[part 4 of 6: packages /DBC_SysDesc_P_CANFD/Pkg_Cluster to /DBC_SysDesc_P_CANFD/Pkg_CompuMethod]
AUTOSAR XML (schema 4-2-2)
package /DBC_SysDesc_P_CANFD/Pkg_Cluster  (continued)
  can cluster P_CANFD: baudrate=500000, protocol-name=CAN, can-fd-baudrate=2000000  (continued)
    can physical channel P_CANFD_Channel: comm-connectors=Conn_P_CANFD_MVCU  (continued)
      frame MCUM_0xCA: id 0xCA, from MVCU, frame-length=32, can-addressing-mode=STANDARD, can-fd-frame-support=true, can-frame-tx-behavior=CAN-FD
        carries pdu MCUM_0xCA: packing-byte-order=little-endian, start-position=0, update-indication-bit-position=-1
        pdu MCUM_0xCA: length=32, transmission-mode-false-timing=cyclic-timing={time-offset=0.0, time-period=0.01}, transmission-mode-true-timing=cyclic-timing={time-offset=0.0, time-period=0.01}
          transmission-mode-conditions:
            {data-filter={data-filter-type=ALWAYS, max=255, min=0, offset=0}, i-signal-in-i-pdu=MCUM_CRC_CA}
            {data-filter={data-filter-type=ALWAYS, max=15, min=0, offset=0}, i-signal-in-i-pdu=MCUM_RollingCounter_CA}
            {data-filter={data-filter-type=ALWAYS, max=3, min=0, offset=0}, i-signal-in-i-pdu=MCUM_WarningLevel}
            {data-filter={data-filter-type=ALWAYS, max=3, min=0, offset=0}, i-signal-in-i-pdu=MCUM_SelfCheckSts}
            {data-filter={data-filter-type=ALWAYS, max=3, min=0, offset=0}, i-signal-in-i-pdu=MCUM_DrvMotorWorkSts}
            {data-filter={data-filter-type=ALWAYS, max=1, min=0, offset=0}, i-signal-in-i-pdu=MCUM_PowerReduceSts}
            {data-filter={data-filter-type=ALWAYS, max=1, min=0, offset=0}, i-signal-in-i-pdu=MCUM_SystemError}
            {data-filter={data-filter-type=NEW-IS-WITHIN, max=47000, min=0}, i-signal-in-i-pdu=MCUM_DrvMotorRPM}
            {data-filter={data-filter-type=NEW-IS-WITHIN, max=10000, min=0}, i-signal-in-i-pdu=MCUM_ActualTorqueFB}
            {data-filter={data-filter-type=ALWAYS, max=1, min=0, offset=0}, i-signal-in-i-pdu=MCUM_HWRdcFault}
            {data-filter={data-filter-type=ALWAYS, max=1, min=0, offset=0}, i-signal-in-i-pdu=MCUM_LVSystemError}
            {data-filter={data-filter-type=ALWAYS, max=1, min=0, offset=0}, i-signal-in-i-pdu=MCUM_HighVoltPowerOffReq}
            {data-filter={data-filter-type=ALWAYS, max=1, min=0, offset=0}, i-signal-in-i-pdu=MCUM_HVILSts}
            {data-filter={data-filter-type=ALWAYS, max=3, min=0, offset=0}, i-signal-in-i-pdu=MCUM_DragSts}
            {data-filter={data-filter-type=ALWAYS, max=1, min=0, offset=0}, i-signal-in-i-pdu=MCUM_CtrlMode}
            {data-filter={data-filter-type=ALWAYS, max=1, min=0, offset=0}, i-signal-in-i-pdu=MCUM_MotorTempAlarm}
            {data-filter={data-filter-type=ALWAYS, max=1, min=0, offset=0}, i-signal-in-i-pdu=MCUM_HVSystemError}
            {data-filter={data-filter-type=ALWAYS, max=1, min=0, offset=0}, i-signal-in-i-pdu=MCUM_MILlampReq}
            {data-filter={data-filter-type=ALWAYS, max=3, min=0, offset=0}, i-signal-in-i-pdu=MCUM_SeriousWarning_Level}
            {data-filter={data-filter-type=ALWAYS, max=1, min=0, offset=0}, i-signal-in-i-pdu=MCUM_DrvMotorRPMVD}
            {data-filter={data-filter-type=ALWAYS, max=1, min=0, offset=0}, i-signal-in-i-pdu=MCUM_ActualTorqueFBVD}
            {data-filter={data-filter-type=ALWAYS, max=1, min=0, offset=0}, i-signal-in-i-pdu=MCUM_CtrlModeVD}
            {data-filter={data-filter-type=NEW-IS-WITHIN, max=10000, min=0}, i-signal-in-i-pdu=MCUM_MaxTorqueAllow}
            {data-filter={data-filter-type=NEW-IS-WITHIN, max=34000, min=0}, i-signal-in-i-pdu=MCUM_MaxSpeedAllow}
            {data-filter={data-filter-type=ALWAYS, max=10, min=0, offset=0}, i-signal-in-i-pdu=MCUM_WaterPumpLevlReq}
            {data-filter={data-filter-type=ALWAYS, max=3, min=0, offset=0}, i-signal-in-i-pdu=MCUM_ActiveReleaseSts}
            {data-filter={data-filter-type=ALWAYS, max=1, min=0, offset=0}, i-signal-in-i-pdu=MCUM_DCChargRelaySts}
            {data-filter={data-filter-type=ALWAYS, max=1, min=0, offset=0}, i-signal-in-i-pdu=MCUM_Fault_DCChargRelay}
            {data-filter={data-filter-type=NEW-IS-WITHIN, max=10000, min=0}, i-signal-in-i-pdu=MCUM_MinTorqueAllow}
            {data-filter={data-filter-type=NEW-IS-WITHIN, max=10000, min=0, offset=0}, i-signal-in-i-pdu=MCUM_MainWireVolt}
            {data-filter={data-filter-type=ALWAYS, max=250, min=0}, i-signal-in-i-pdu=MCUM_MotorTemp}
            {data-filter={data-filter-type=ALWAYS, max=250, min=0}, i-signal-in-i-pdu=MCUM_IGBTTemp}
            {data-filter={data-filter-type=ALWAYS, max=250, min=0}, i-signal-in-i-pdu=MCUM_InletTemp}
            {data-filter={data-filter-type=NEW-IS-WITHIN, max=20000, min=0}, i-signal-in-i-pdu=MCUM_MainWireCurr}
            {data-filter={data-filter-type=ALWAYS, max=1, min=0, offset=0}, i-signal-in-i-pdu=MCUM_TMS_MotSelfHeatEnSts}
            {data-filter={data-filter-type=ALWAYS, max=7, min=0, offset=0}, i-signal-in-i-pdu=MCUM_TMS_MotSelfHeatLvlFb}
            {data-filter={data-filter-type=ALWAYS, max=1, min=0, offset=0}, i-signal-in-i-pdu=MCUM_HeatPwrAllwd}
            {data-filter={data-filter-type=ALWAYS, max=3, min=0, offset=0}, i-signal-in-i-pdu=MCUM_HeatFdBck}
            {data-filter={data-filter-type=ALWAYS, max=1, min=0, offset=0}, i-signal-in-i-pdu=MCUM_RPowerReduceSts}
            {data-filter={data-filter-type=ALWAYS, max=128, min=0, offset=0}, i-signal-in-i-pdu=MCUM_HeatPwrAct}
            {data-filter={data-filter-type=ALWAYS, max=128, min=0, offset=0}, i-signal-in-i-pdu=MCUM_HeatPwrMax}
            {data-filter={data-filter-type=ALWAYS, max=31, min=0, offset=0}, i-signal-in-i-pdu=MCUM_HeatPwrAval}
            {data-filter={data-filter-type=ALWAYS, max=1, min=0, offset=0}, i-signal-in-i-pdu=MCUM_RCtrlMode}
            {data-filter={data-filter-type=ALWAYS, max=3, min=0, offset=0}, i-signal-in-i-pdu=MCUM_RWarningLevel}
            {data-filter={data-filter-type=ALWAYS, max=3, min=0, offset=0}, i-signal-in-i-pdu=MCUM_RSelfCheckSts}
            {data-filter={data-filter-type=ALWAYS, max=3, min=0, offset=0}, i-signal-in-i-pdu=MCUM_RDrvMotorWorkSts}
            {data-filter={data-filter-type=ALWAYS, max=1, min=0, offset=0}, i-signal-in-i-pdu=MCUM_RCtrlModeVD}
            {data-filter={data-filter-type=ALWAYS, max=1, min=0, offset=0}, i-signal-in-i-pdu=MCUM_RHWRdcFault}
            {data-filter={data-filter-type=ALWAYS, max=1, min=0, offset=0}, i-signal-in-i-pdu=MCUM_RDrvMotorRPMVD}
            {data-filter={data-filter-type=ALWAYS, max=1, min=0, offset=0}, i-signal-in-i-pdu=MCUM_RActualTorqueFBVD}
            {data-filter={data-filter-type=ALWAYS, max=65535, min=0, offset=0}, i-signal-in-i-pdu=MCUM_RDrvMotorRPM}
            {data-filter={data-filter-type=ALWAYS, max=65535, min=0, offset=0}, i-signal-in-i-pdu=MCUM_RActualTorqueFB}
          signal MCUM_CRC_CA: start 0, 8 bit, little-endian, init-value=0, base-type=uint8, implementation-data-type=DT_MCUM_CRC_CA, update-indication-bit-position=-1
          signal MCUM_RollingCounter_CA: start 8, 4 bit, little-endian, init-value=0, base-type=uint8, implementation-data-type=DT_MCUM_RollingCounter_CA, update-indication-bit-position=-1
          signal MCUM_WarningLevel: start 16, 2 bit, little-endian, init-value=0, base-type=uint8, implementation-data-type=DT_MCUM_WarningLevel, update-indication-bit-position=-1
          signal MCUM_SelfCheckSts: start 18, 2 bit, little-endian, init-value=0, base-type=uint8, implementation-data-type=DT_MCUM_SelfCheckSts, update-indication-bit-position=-1
          signal MCUM_DrvMotorWorkSts: start 20, 2 bit, little-endian, init-value=0, base-type=uint8, implementation-data-type=DT_MCUM_DrvMotorWorkSts, update-indication-bit-position=-1
          signal MCUM_PowerReduceSts: start 22, 1 bit, little-endian, init-value=0, base-type=uint8, implementation-data-type=DT_MCUM_PowerReduceSts, update-indication-bit-position=-1
          signal MCUM_SystemError: start 23, 1 bit, little-endian, init-value=0, base-type=uint8, implementation-data-type=DT_MCUM_SystemError, update-indication-bit-position=-1
          signal MCUM_DrvMotorRPM: start 24, 16 bit, little-endian, init-value=0, base-type=uint16, implementation-data-type=DT_MCUM_DrvMotorRPM, update-indication-bit-position=-1
          signal MCUM_ActualTorqueFB: start 40, 16 bit, little-endian, init-value=0, base-type=uint16, implementation-data-type=DT_MCUM_ActualTorqueFB, update-indication-bit-position=-1
          signal MCUM_HWRdcFault: start 56, 1 bit, little-endian, init-value=0, base-type=uint8, implementation-data-type=DT_MCUM_HWRdcFault, update-indication-bit-position=-1
          signal MCUM_LVSystemError: start 57, 1 bit, little-endian, init-value=0, base-type=uint8, implementation-data-type=DT_MCUM_LVSystemError, update-indication-bit-position=-1
          signal MCUM_HighVoltPowerOffReq: start 58, 1 bit, little-endian, init-value=0, base-type=uint8, implementation-data-type=DT_MCUM_HighVoltPowerOffReq, update-indication-bit-position=-1
          signal MCUM_HVILSts: start 59, 1 bit, little-endian, init-value=0, base-type=uint8, implementation-data-type=DT_MCUM_HVILSts, update-indication-bit-position=-1
          signal MCUM_DragSts: start 60, 2 bit, little-endian, init-value=0, base-type=uint8, implementation-data-type=DT_MCUM_DragSts, update-indication-bit-position=-1
          signal MCUM_CtrlMode: start 62, 1 bit, little-endian, init-value=0, base-type=uint8, implementation-data-type=DT_MCUM_CtrlMode, update-indication-bit-position=-1
          signal MCUM_MotorTempAlarm: start 63, 1 bit, little-endian, init-value=0, base-type=uint8, implementation-data-type=DT_MCUM_MotorTempAlarm, update-indication-bit-position=-1
          signal MCUM_HVSystemError: start 64, 1 bit, little-endian, init-value=0, base-type=uint8, implementation-data-type=DT_MCUM_HVSystemError, update-indication-bit-position=-1
          signal MCUM_MILlampReq: start 65, 1 bit, little-endian, init-value=0, base-type=uint8, implementation-data-type=DT_MCUM_MILlampReq, update-indication-bit-position=-1
          signal MCUM_SeriousWarning_Level: start 66, 2 bit, little-endian, init-value=0, base-type=uint8, implementation-data-type=DT_MCUM_SeriousWarning_Level, update-indication-bit-position=-1
          signal MCUM_DrvMotorRPMVD: start 68, 1 bit, little-endian, init-value=0, base-type=uint8, implementation-data-type=DT_MCUM_DrvMotorRPMVD, update-indication-bit-position=-1
          signal MCUM_ActualTorqueFBVD: start 69, 1 bit, little-endian, init-value=0, base-type=uint8, implementation-data-type=DT_MCUM_ActualTorqueFBVD, update-indication-bit-position=-1
          signal MCUM_CtrlModeVD: start 70, 1 bit, little-endian, init-value=0, base-type=uint8, implementation-data-type=DT_MCUM_CtrlModeVD, update-indication-bit-position=-1
          signal MCUM_MaxTorqueAllow: start 72, 16 bit, little-endian, init-value=0, base-type=uint16, implementation-data-type=DT_MCUM_MaxTorqueAllow, update-indication-bit-position=-1
          signal MCUM_MaxSpeedAllow: start 88, 16 bit, little-endian, init-value=0, base-type=uint16, implementation-data-type=DT_MCUM_MaxSpeedAllow, update-indication-bit-position=-1
          signal MCUM_WaterPumpLevlReq: start 104, 4 bit, little-endian, init-value=0, base-type=uint8, implementation-data-type=DT_MCUM_WaterPumpLevlReq, update-indication-bit-position=-1
          signal MCUM_ActiveReleaseSts: start 108, 2 bit, little-endian, init-value=0, base-type=uint8, implementation-data-type=DT_MCUM_ActiveReleaseSts, update-indication-bit-position=-1
          signal MCUM_DCChargRelaySts: start 110, 1 bit, little-endian, init-value=0, base-type=uint8, implementation-data-type=DT_MCUM_DCChargRelaySts, update-indication-bit-position=-1
          signal MCUM_Fault_DCChargRelay: start 111, 1 bit, little-endian, init-value=0, base-type=uint8, implementation-data-type=DT_MCUM_Fault_DCChargRelay, update-indication-bit-position=-1
          signal MCUM_MinTorqueAllow: start 112, 16 bit, little-endian, init-value=0, base-type=uint16, implementation-data-type=DT_MCUM_MinTorqueAllow, update-indication-bit-position=-1
          signal MCUM_MainWireVolt: start 128, 16 bit, little-endian, init-value=0, base-type=uint16, implementation-data-type=DT_MCUM_MainWireVolt, update-indication-bit-position=-1
          signal MCUM_MotorTemp: start 144, 8 bit, little-endian, init-value=0, base-type=uint8, implementation-data-type=DT_MCUM_MotorTemp, update-indication-bit-position=-1
          signal MCUM_IGBTTemp: start 152, 8 bit, little-endian, init-value=0, base-type=uint8, implementation-data-type=DT_MCUM_IGBTTemp, update-indication-bit-position=-1
          signal MCUM_InletTemp: start 160, 8 bit, little-endian, init-value=0, base-type=uint8, implementation-data-type=DT_MCUM_InletTemp, update-indication-bit-position=-1
          signal MCUM_MainWireCurr: start 168, 16 bit, little-endian, init-value=0, base-type=uint16, implementation-data-type=DT_MCUM_MainWireCurr, update-indication-bit-position=-1
          signal MCUM_TMS_MotSelfHeatEnSts: start 184, 1 bit, little-endian, init-value=0, base-type=uint8, implementation-data-type=DT_MCUM_TMS_MotSelfHeatEnSts, update-indication-bit-position=-1
          signal MCUM_TMS_MotSelfHeatLvlFb: start 185, 3 bit, little-endian, init-value=0, base-type=uint8, implementation-data-type=DT_MCUM_TMS_MotSelfHeatLvlFb, update-indication-bit-position=-1
          signal MCUM_HeatPwrAllwd: start 188, 1 bit, little-endian, init-value=0, base-type=uint8, implementation-data-type=DT_MCUM_HeatPwrAllwd, update-indication-bit-position=-1
          signal MCUM_HeatFdBck: start 189, 2 bit, little-endian, init-value=0, base-type=uint8, implementation-data-type=DT_MCUM_HeatFdBck, update-indication-bit-position=-1
          signal MCUM_RPowerReduceSts: start 191, 1 bit, little-endian, init-value=0, base-type=uint8, implementation-data-type=DT_MCUM_RPowerReduceSts, update-indication-bit-position=-1
          signal MCUM_HeatPwrAct: start 192, 8 bit, little-endian, init-value=0, base-type=uint8, implementation-data-type=DT_MCUM_HeatPwrAct, update-indication-bit-position=-1
          signal MCUM_HeatPwrMax: start 200, 8 bit, little-endian, init-value=0, base-type=uint8, implementation-data-type=DT_MCUM_HeatPwrMax, update-indication-bit-position=-1
          signal MCUM_HeatPwrAval: start 208, 5 bit, little-endian, init-value=0, base-type=uint8, implementation-data-type=DT_MCUM_HeatPwrAval, update-indication-bit-position=-1
          signal MCUM_RCtrlMode: start 213, 1 bit, little-endian, init-value=0, base-type=uint8, implementation-data-type=DT_MCUM_RCtrlMode, update-indication-bit-position=-1
          signal MCUM_RWarningLevel: start 214, 2 bit, little-endian, init-value=0, base-type=uint8, implementation-data-type=DT_MCUM_RWarningLevel, update-indication-bit-position=-1
          signal MCUM_RSelfCheckSts: start 216, 2 bit, little-endian, init-value=0, base-type=uint8, implementation-data-type=DT_MCUM_RSelfCheckSts, update-indication-bit-position=-1
          signal MCUM_RDrvMotorWorkSts: start 218, 2 bit, little-endian, init-value=0, base-type=uint8, implementation-data-type=DT_MCUM_RDrvMotorWorkSts, update-indication-bit-position=-1
          signal MCUM_RCtrlModeVD: start 220, 1 bit, little-endian, init-value=0, base-type=uint8, implementation-data-type=DT_MCUM_RCtrlModeVD, update-indication-bit-position=-1
          signal MCUM_RHWRdcFault: start 221, 1 bit, little-endian, init-value=0, base-type=uint8, implementation-data-type=DT_MCUM_RHWRdcFault, update-indication-bit-position=-1
          signal MCUM_RDrvMotorRPMVD: start 222, 1 bit, little-endian, init-value=0, base-type=uint8, implementation-data-type=DT_MCUM_RDrvMotorRPMVD, update-indication-bit-position=-1
          signal MCUM_RActualTorqueFBVD: start 223, 1 bit, little-endian, init-value=0, base-type=uint8, implementation-data-type=DT_MCUM_RActualTorqueFBVD, update-indication-bit-position=-1
          signal MCUM_RDrvMotorRPM: start 224, 16 bit, little-endian, init-value=0, base-type=uint16, implementation-data-type=DT_MCUM_RDrvMotorRPM, update-indication-bit-position=-1
          signal MCUM_RActualTorqueFB: start 240, 16 bit, little-endian, init-value=0, base-type=uint16, implementation-data-type=DT_MCUM_RActualTorqueFB, update-indication-bit-position=-1
      frame MCUM_0x6F8: id 0x6F8, from MVCU, frame-length=64, can-addressing-mode=STANDARD, can-fd-frame-support=true, can-frame-tx-behavior=CAN-FD
        carries pdu MCUM_0x6F8: packing-byte-order=little-endian, start-position=0, update-indication-bit-position=-1
        pdu MCUM_0x6F8: length=64, transmission-mode-false-timing=cyclic-timing={time-offset=0.0, time-period=1.0}, transmission-mode-true-timing=cyclic-timing={time-offset=0.0, time-period=1.0}
          transmission-mode-conditions:
            {data-filter={data-filter-type=ALWAYS, max=255, min=0, offset=0}, i-signal-in-i-pdu=MCUM_UDS_SW{1..10}}
            {data-filter={data-filter-type=ALWAYS, max=255, min=0, offset=0}, i-signal-in-i-pdu=MCUM_UDS_HW{1..10}}
            {data-filter={data-filter-type=ALWAYS, max=255, min=0, offset=0}, i-signal-in-i-pdu=MCUM_UDS_Boot{1..10}}
            {data-filter={data-filter-type=ALWAYS, max=255, min=0, offset=0}, i-signal-in-i-pdu=MCUM_UDS_ProductModel{1..16}}
            {data-filter={data-filter-type=ALWAYS, max=255, min=0, offset=0}, i-signal-in-i-pdu=MCUM_UDS_Supplier{1..6}}
          signal MCUM_UDS_SW1: start 0, 8 bit, little-endian, init-value=0, base-type=uint8, implementation-data-type=DT_MCUM_UDS_SW1, update-indication-bit-position=-1
          signal MCUM_UDS_SW2: start 8, 8 bit, little-endian, init-value=0, base-type=uint8, implementation-data-type=DT_MCUM_UDS_SW2, update-indication-bit-position=-1
          signal MCUM_UDS_SW3: start 16, 8 bit, little-endian, init-value=0, base-type=uint8, implementation-data-type=DT_MCUM_UDS_SW3, update-indication-bit-position=-1
          signal MCUM_UDS_SW4: start 24, 8 bit, little-endian, init-value=0, base-type=uint8, implementation-data-type=DT_MCUM_UDS_SW4, update-indication-bit-position=-1
          signal MCUM_UDS_SW5: start 32, 8 bit, little-endian, init-value=0, base-type=uint8, implementation-data-type=DT_MCUM_UDS_SW5, update-indication-bit-position=-1
          signal MCUM_UDS_SW6: start 40, 8 bit, little-endian, init-value=0, base-type=uint8, implementation-data-type=DT_MCUM_UDS_SW6, update-indication-bit-position=-1
          signal MCUM_UDS_SW7: start 48, 8 bit, little-endian, init-value=0, base-type=uint8, implementation-data-type=DT_MCUM_UDS_SW7, update-indication-bit-position=-1
          signal MCUM_UDS_SW8: start 56, 8 bit, little-endian, init-value=0, base-type=uint8, implementation-data-type=DT_MCUM_UDS_SW8, update-indication-bit-position=-1
          signal MCUM_UDS_SW9: start 64, 8 bit, little-endian, init-value=0, base-type=uint8, implementation-data-type=DT_MCUM_UDS_SW9, update-indication-bit-position=-1
          signal MCUM_UDS_SW10: start 72, 8 bit, little-endian, init-value=0, base-type=uint8, implementation-data-type=DT_MCUM_UDS_SW10, update-indication-bit-position=-1
          signal MCUM_UDS_HW1: start 80, 8 bit, little-endian, init-value=0, base-type=uint8, implementation-data-type=DT_MCUM_UDS_HW1, update-indication-bit-position=-1
          signal MCUM_UDS_HW2: start 88, 8 bit, little-endian, init-value=0, base-type=uint8, implementation-data-type=DT_MCUM_UDS_HW2, update-indication-bit-position=-1
          signal MCUM_UDS_HW3: start 96, 8 bit, little-endian, init-value=0, base-type=uint8, implementation-data-type=DT_MCUM_UDS_HW3, update-indication-bit-position=-1
          signal MCUM_UDS_HW4: start 104, 8 bit, little-endian, init-value=0, base-type=uint8, implementation-data-type=DT_MCUM_UDS_HW4, update-indication-bit-position=-1
          signal MCUM_UDS_HW5: start 112, 8 bit, little-endian, init-value=0, base-type=uint8, implementation-data-type=DT_MCUM_UDS_HW5, update-indication-bit-position=-1
          signal MCUM_UDS_HW6: start 120, 8 bit, little-endian, init-value=0, base-type=uint8, implementation-data-type=DT_MCUM_UDS_HW6, update-indication-bit-position=-1
          signal MCUM_UDS_HW7: start 128, 8 bit, little-endian, init-value=0, base-type=uint8, implementation-data-type=DT_MCUM_UDS_HW7, update-indication-bit-position=-1
          signal MCUM_UDS_HW8: start 136, 8 bit, little-endian, init-value=0, base-type=uint8, implementation-data-type=DT_MCUM_UDS_HW8, update-indication-bit-position=-1
          signal MCUM_UDS_HW9: start 144, 8 bit, little-endian, init-value=0, base-type=uint8, implementation-data-type=DT_MCUM_UDS_HW9, update-indication-bit-position=-1
          signal MCUM_UDS_HW10: start 152, 8 bit, little-endian, init-value=0, base-type=uint8, implementation-data-type=DT_MCUM_UDS_HW10, update-indication-bit-position=-1
          signal MCUM_UDS_Boot1: start 160, 8 bit, little-endian, init-value=0, base-type=uint8, implementation-data-type=DT_MCUM_UDS_Boot1, update-indication-bit-position=-1
          signal MCUM_UDS_Boot2: start 168, 8 bit, little-endian, init-value=0, base-type=uint8, implementation-data-type=DT_MCUM_UDS_Boot2, update-indication-bit-position=-1
          signal MCUM_UDS_Boot3: start 176, 8 bit, little-endian, init-value=0, base-type=uint8, implementation-data-type=DT_MCUM_UDS_Boot3, update-indication-bit-position=-1
          signal MCUM_UDS_Boot4: start 184, 8 bit, little-endian, init-value=0, base-type=uint8, implementation-data-type=DT_MCUM_UDS_Boot4, update-indication-bit-position=-1
          signal MCUM_UDS_Boot5: start 192, 8 bit, little-endian, init-value=0, base-type=uint8, implementation-data-type=DT_MCUM_UDS_Boot5, update-indication-bit-position=-1
          signal MCUM_UDS_Boot6: start 200, 8 bit, little-endian, init-value=0, base-type=uint8, implementation-data-type=DT_MCUM_UDS_Boot6, update-indication-bit-position=-1
          signal MCUM_UDS_Boot7: start 208, 8 bit, little-endian, init-value=0, base-type=uint8, implementation-data-type=DT_MCUM_UDS_Boot7, update-indication-bit-position=-1
          signal MCUM_UDS_Boot8: start 216, 8 bit, little-endian, init-value=0, base-type=uint8, implementation-data-type=DT_MCUM_UDS_Boot8, update-indication-bit-position=-1
          signal MCUM_UDS_Boot9: start 224, 8 bit, little-endian, init-value=0, base-type=uint8, implementation-data-type=DT_MCUM_UDS_Boot9, update-indication-bit-position=-1
          signal MCUM_UDS_Boot10: start 232, 8 bit, little-endian, init-value=0, base-type=uint8, implementation-data-type=DT_MCUM_UDS_Boot10, update-indication-bit-position=-1
          signal MCUM_UDS_ProductModel1: start 240, 8 bit, little-endian, init-value=0, base-type=uint8, implementation-data-type=DT_MCUM_UDS_ProductModel1, update-indication-bit-position=-1
          signal MCUM_UDS_ProductModel2: start 248, 8 bit, little-endian, init-value=0, base-type=uint8, implementation-data-type=DT_MCUM_UDS_ProductModel2, update-indication-bit-position=-1
          signal MCUM_UDS_ProductModel3: start 256, 8 bit, little-endian, init-value=0, base-type=uint8, implementation-data-type=DT_MCUM_UDS_ProductModel3, update-indication-bit-position=-1
          signal MCUM_UDS_ProductModel4: start 264, 8 bit, little-endian, init-value=0, base-type=uint8, implementation-data-type=DT_MCUM_UDS_ProductModel4, update-indication-bit-position=-1
          signal MCUM_UDS_ProductModel5: start 272, 8 bit, little-endian, init-value=0, base-type=uint8, implementation-data-type=DT_MCUM_UDS_ProductModel5, update-indication-bit-position=-1
          signal MCUM_UDS_ProductModel6: start 280, 8 bit, little-endian, init-value=0, base-type=uint8, implementation-data-type=DT_MCUM_UDS_ProductModel6, update-indication-bit-position=-1
          signal MCUM_UDS_ProductModel7: start 288, 8 bit, little-endian, init-value=0, base-type=uint8, implementation-data-type=DT_MCUM_UDS_ProductModel7, update-indication-bit-position=-1
          signal MCUM_UDS_ProductModel8: start 296, 8 bit, little-endian, init-value=0, base-type=uint8, implementation-data-type=DT_MCUM_UDS_ProductModel8, update-indication-bit-position=-1
          signal MCUM_UDS_ProductModel9: start 304, 8 bit, little-endian, init-value=0, base-type=uint8, implementation-data-type=DT_MCUM_UDS_ProductModel9, update-indication-bit-position=-1
          signal MCUM_UDS_ProductModel10: start 312, 8 bit, little-endian, init-value=0, base-type=uint8, implementation-data-type=DT_MCUM_UDS_ProductModel10, update-indication-bit-position=-1
          signal MCUM_UDS_ProductModel11: start 320, 8 bit, little-endian, init-value=0, base-type=uint8, implementation-data-type=DT_MCUM_UDS_ProductModel11, update-indication-bit-position=-1
          signal MCUM_UDS_ProductModel12: start 328, 8 bit, little-endian, init-value=0, base-type=uint8, implementation-data-type=DT_MCUM_UDS_ProductModel12, update-indication-bit-position=-1
          signal MCUM_UDS_ProductModel13: start 336, 8 bit, little-endian, init-value=0, base-type=uint8, implementation-data-type=DT_MCUM_UDS_ProductModel13, update-indication-bit-position=-1
          signal MCUM_UDS_ProductModel14: start 344, 8 bit, little-endian, init-value=0, base-type=uint8, implementation-data-type=DT_MCUM_UDS_ProductModel14, update-indication-bit-position=-1
          signal MCUM_UDS_ProductModel15: start 352, 8 bit, little-endian, init-value=0, base-type=uint8, implementation-data-type=DT_MCUM_UDS_ProductModel15, update-indication-bit-position=-1
          signal MCUM_UDS_ProductModel16: start 360, 8 bit, little-endian, init-value=0, base-type=uint8, implementation-data-type=DT_MCUM_UDS_ProductModel16, update-indication-bit-position=-1
          signal MCUM_UDS_Supplier1: start 368, 8 bit, little-endian, init-value=0, base-type=uint8, implementation-data-type=DT_MCUM_UDS_Supplier1, update-indication-bit-position=-1
          signal MCUM_UDS_Supplier2: start 376, 8 bit, little-endian, init-value=0, base-type=uint8, implementation-data-type=DT_MCUM_UDS_Supplier2, update-indication-bit-position=-1
          signal MCUM_UDS_Supplier3: start 384, 8 bit, little-endian, init-value=0, base-type=uint8, implementation-data-type=DT_MCUM_UDS_Supplier3, update-indication-bit-position=-1
          signal MCUM_UDS_Supplier4: start 392, 8 bit, little-endian, init-value=0, base-type=uint8, implementation-data-type=DT_MCUM_UDS_Supplier4, update-indication-bit-position=-1
          signal MCUM_UDS_Supplier5: start 400, 8 bit, little-endian, init-value=0, base-type=uint8, implementation-data-type=DT_MCUM_UDS_Supplier5, update-indication-bit-position=-1
          signal MCUM_UDS_Supplier6: start 408, 8 bit, little-endian, init-value=0, base-type=uint8, implementation-data-type=DT_MCUM_UDS_Supplier6, update-indication-bit-position=-1
      frame VCU_0x514: id 0x514, from MVCU, frame-length=8, can-addressing-mode=STANDARD, can-fd-frame-support=true, can-frame-tx-behavior=CAN-FD
        carries pdu VCU_0x514: packing-byte-order=little-endian, start-position=0, update-indication-bit-position=-1
        pdu VCU_0x514: length=8, transmission-mode-false-timing=cyclic-timing={time-offset=0.0, time-period=0.1}, transmission-mode-true-timing=cyclic-timing={time-offset=0.0, time-period=0.1}
          transmission-mode-conditions:
            {data-filter={data-filter-type=ALWAYS, max=255, min=0, offset=0}, i-signal-in-i-pdu=VCU_FuelConsumption}
            {data-filter={data-filter-type=ALWAYS, max=1, min=0, offset=0}, i-signal-in-i-pdu=VCU_SVSLamp}
            {data-filter={data-filter-type=ALWAYS, max=1, min=0, offset=0}, i-signal-in-i-pdu=VCU_MilLamp}
            {data-filter={data-filter-type=ALWAYS, max=1, min=0, offset=0}, i-signal-in-i-pdu=VCU_SinglePedalSts_ID514}
            {data-filter={data-filter-type=ALWAYS, max=1, min=0, offset=0}, i-signal-in-i-pdu=VCU_GearLevelPosFault_ID514}
            {data-filter={data-filter-type=ALWAYS, max=1, min=0, offset=0}, i-signal-in-i-pdu=VCU_EngineStartFailure_ID514}
            {data-filter={data-filter-type=ALWAYS, max=1, min=0, offset=0}, i-signal-in-i-pdu=VCU_ParkBeforeFuelup}
            {data-filter={data-filter-type=ALWAYS, max=1, min=0, offset=0}, i-signal-in-i-pdu=VCU_REsystemFaultSts_ID514}
            {data-filter={data-filter-type=ALWAYS, max=1, min=0, offset=0}, i-signal-in-i-pdu=VCU_EngineRunAllowFlg_ID514}
            {data-filter={data-filter-type=ALWAYS, max=7, min=0, offset=0}, i-signal-in-i-pdu=VCU_InverterTip}
            {data-filter={data-filter-type=ALWAYS, max=3, min=0, offset=0}, i-signal-in-i-pdu=VCU_EMSRepairModeSts}
            {data-filter={data-filter-type=ALWAYS, max=1, min=0, offset=0}, i-signal-in-i-pdu=VCU_FuelTankFlapSts}
            {data-filter={data-filter-type=ALWAYS, max=1, min=0, offset=0}, i-signal-in-i-pdu=VCU_REsystemSts_ID514}
            {data-filter={data-filter-type=ALWAYS, max=3, min=0, offset=0}, i-signal-in-i-pdu=VCU_PowerModeAllow}
            {data-filter={data-filter-type=ALWAYS, max=1, min=0, offset=0}, i-signal-in-i-pdu=VCU_PowerModeSwitchMsg}
            {data-filter={data-filter-type=ALWAYS, max=1, min=0, offset=0}, i-signal-in-i-pdu=VCU_HighVoltFailed_M}
            {data-filter={data-filter-type=ALWAYS, max=1, min=0, offset=0}, i-signal-in-i-pdu=VCU_HighVoltFailed_S}
            {data-filter={data-filter-type=ALWAYS, max=1, min=0, offset=0}, i-signal-in-i-pdu=VCU_BrakeBeforeGear}
            {data-filter={data-filter-type=ALWAYS, max=1, min=0, offset=0}, i-signal-in-i-pdu=VCU_ParkBeforeGear}
            {data-filter={data-filter-type=ALWAYS, max=1, min=0, offset=0}, i-signal-in-i-pdu=VCU_GearBeforDriving}
            {data-filter={data-filter-type=ALWAYS, max=1, min=0, offset=0}, i-signal-in-i-pdu=VCU_UnlockBeforeDriving}
            {data-filter={data-filter-type=ALWAYS, max=1, min=0, offset=0}, i-signal-in-i-pdu=VCU_PreventSliding}
            {data-filter={data-filter-type=ALWAYS, max=1, min=0, offset=0}, i-signal-in-i-pdu=VCU_MMErrorSts}
            {data-filter={data-filter-type=ALWAYS, max=1, min=0, offset=0}, i-signal-in-i-pdu=VCU_ShowCarModeSts}
            {data-filter={data-filter-type=ALWAYS, max=1, min=0, offset=0}, i-signal-in-i-pdu=VCU_PGearFlashSts}
            {data-filter={data-filter-type=ALWAYS, max=1, min=0, offset=0}, i-signal-in-i-pdu=VCU_ACConnectSts}
            {data-filter={data-filter-type=ALWAYS, max=1, min=0, offset=0}, i-signal-in-i-pdu=VCU_DcChgPwrSts}
            {data-filter={data-filter-type=ALWAYS, max=1, min=0, offset=0}, i-signal-in-i-pdu=VCU_DriverAssistProhibitSts_ID514}
            {data-filter={data-filter-type=ALWAYS, max=1, min=0, offset=0}, i-signal-in-i-pdu=VCU_MilLampRequest_ID514}
            {data-filter={data-filter-type=ALWAYS, max=200, min=0, offset=0}, i-signal-in-i-pdu=VCU_CcmHvilInSigFreq_FB}
            {data-filter={data-filter-type=ALWAYS, max=100, min=0, offset=0}, i-signal-in-i-pdu=VCU_CcmHvilInSigDuty_FB}
            {data-filter={data-filter-type=ALWAYS, max=3, min=0, offset=0}, i-signal-in-i-pdu=VCU_FuelDectionModeSts}
            {data-filter={data-filter-type=ALWAYS, max=1, min=0, offset=0}, i-signal-in-i-pdu=VCU_EnergyCtrlMode}
            {data-filter={data-filter-type=ALWAYS, max=1, min=0, offset=0}, i-signal-in-i-pdu=VCU_VehSpdLimtRemind_ID514}
            {data-filter={data-filter-type=ALWAYS, max=1, min=0, offset=0}, i-signal-in-i-pdu=VCU_TurtleLamp}
          signal VCU_FuelConsumption: start 0, 8 bit, little-endian, init-value=0, base-type=uint8, implementation-data-type=DT_VCU_FuelConsumption, update-indication-bit-position=-1
          signal VCU_SVSLamp: start 8, 1 bit, little-endian, init-value=0, base-type=uint8, implementation-data-type=DT_VCU_SVSLamp, update-indication-bit-position=-1
          signal VCU_MilLamp: start 9, 1 bit, little-endian, init-value=0, base-type=uint8, implementation-data-type=DT_VCU_MilLamp, update-indication-bit-position=-1
          signal VCU_SinglePedalSts_ID514: start 10, 1 bit, little-endian, init-value=0, base-type=uint8, implementation-data-type=DT_VCU_SinglePedalSts_ID514, update-indication-bit-position=-1
          signal VCU_GearLevelPosFault_ID514: start 11, 1 bit, little-endian, init-value=0, base-type=uint8, implementation-data-type=DT_VCU_GearLevelPosFault_ID514, update-indication-bit-position=-1
          signal VCU_EngineStartFailure_ID514: start 12, 1 bit, little-endian, init-value=0, base-type=uint8, implementation-data-type=DT_VCU_EngineStartFailure_ID514, update-indication-bit-position=-1
          signal VCU_ParkBeforeFuelup: start 13, 1 bit, little-endian, init-value=0, base-type=uint8, implementation-data-type=DT_VCU_ParkBeforeFuelup, update-indication-bit-position=-1
          signal VCU_REsystemFaultSts_ID514: start 14, 1 bit, little-endian, init-value=0, base-type=uint8, implementation-data-type=DT_VCU_REsystemFaultSts_ID514, update-indication-bit-position=-1
          signal VCU_EngineRunAllowFlg_ID514: start 15, 1 bit, little-endian, init-value=0, base-type=uint8, implementation-data-type=DT_VCU_EngineRunAllowFlg_ID514, update-indication-bit-position=-1
          signal VCU_InverterTip: start 16, 3 bit, little-endian, init-value=0, base-type=uint8, implementation-data-type=DT_VCU_InverterTip, update-indication-bit-position=-1
          signal VCU_EMSRepairModeSts: start 19, 2 bit, little-endian, init-value=0, base-type=uint8, implementation-data-type=DT_VCU_EMSRepairModeSts, update-indication-bit-position=-1
          signal VCU_FuelTankFlapSts: start 21, 1 bit, little-endian, init-value=0, base-type=uint8, implementation-data-type=DT_VCU_FuelTankFlapSts, update-indication-bit-position=-1
          signal VCU_REsystemSts_ID514: start 22, 1 bit, little-endian, init-value=0, base-type=uint8, implementation-data-type=DT_VCU_REsystemSts_ID514, update-indication-bit-position=-1
          signal VCU_PowerModeAllow: start 23, 2 bit, little-endian, init-value=0, base-type=uint8, implementation-data-type=DT_VCU_PowerModeAllow, update-indication-bit-position=-1
          signal VCU_PowerModeSwitchMsg: start 25, 1 bit, little-endian, init-value=0, base-type=uint8, implementation-data-type=DT_VCU_PowerModeSwitchMsg, update-indication-bit-position=-1
          signal VCU_HighVoltFailed_M: start 26, 1 bit, little-endian, init-value=0, base-type=uint8, implementation-data-type=DT_VCU_HighVoltFailed_M, update-indication-bit-position=-1
          signal VCU_HighVoltFailed_S: start 27, 1 bit, little-endian, init-value=0, base-type=uint8, implementation-data-type=DT_VCU_HighVoltFailed_S, update-indication-bit-position=-1
          signal VCU_BrakeBeforeGear: start 28, 1 bit, little-endian, init-value=0, base-type=uint8, implementation-data-type=DT_VCU_BrakeBeforeGear, update-indication-bit-position=-1
          signal VCU_ParkBeforeGear: start 29, 1 bit, little-endian, init-value=0, base-type=uint8, implementation-data-type=DT_VCU_ParkBeforeGear, update-indication-bit-position=-1
          signal VCU_GearBeforDriving: start 30, 1 bit, little-endian, init-value=0, base-type=uint8, implementation-data-type=DT_VCU_GearBeforDriving, update-indication-bit-position=-1
          signal VCU_UnlockBeforeDriving: start 31, 1 bit, little-endian, init-value=0, base-type=uint8, implementation-data-type=DT_VCU_UnlockBeforeDriving, update-indication-bit-position=-1
          signal VCU_PreventSliding: start 32, 1 bit, little-endian, init-value=0, base-type=uint8, implementation-data-type=DT_VCU_PreventSliding, update-indication-bit-position=-1
          signal VCU_MMErrorSts: start 33, 1 bit, little-endian, init-value=0, base-type=uint8, implementation-data-type=DT_VCU_MMErrorSts, update-indication-bit-position=-1
          signal VCU_ShowCarModeSts: start 34, 1 bit, little-endian, init-value=0, base-type=uint8, implementation-data-type=DT_VCU_ShowCarModeSts, update-indication-bit-position=-1
          signal VCU_PGearFlashSts: start 35, 1 bit, little-endian, init-value=0, base-type=uint8, implementation-data-type=DT_VCU_PGearFlashSts, update-indication-bit-position=-1
          signal VCU_ACConnectSts: start 36, 1 bit, little-endian, init-value=0, base-type=uint8, implementation-data-type=DT_VCU_ACConnectSts, update-indication-bit-position=-1
          signal VCU_DcChgPwrSts: start 37, 1 bit, little-endian, init-value=0, base-type=uint8, implementation-data-type=DT_VCU_DcChgPwrSts, update-indication-bit-position=-1
          signal VCU_DriverAssistProhibitSts_ID514: start 38, 1 bit, little-endian, init-value=0, base-type=uint8, implementation-data-type=DT_VCU_DriverAssistProhibitSts_ID514, update-indication-bit-position=-1
          signal VCU_MilLampRequest_ID514: start 39, 1 bit, little-endian, init-value=0, base-type=uint8, implementation-data-type=DT_VCU_MilLampRequest_ID514, update-indication-bit-position=-1
          signal VCU_CcmHvilInSigFreq_FB: start 40, 8 bit, little-endian, init-value=0, base-type=uint8, implementation-data-type=DT_VCU_CcmHvilInSigFreq_FB, update-indication-bit-position=-1
          signal VCU_CcmHvilInSigDuty_FB: start 48, 8 bit, little-endian, init-value=0, base-type=uint8, implementation-data-type=DT_VCU_CcmHvilInSigDuty_FB, update-indication-bit-position=-1
          signal VCU_FuelDectionModeSts: start 56, 2 bit, little-endian, init-value=0, base-type=uint8, implementation-data-type=DT_VCU_FuelDectionModeSts, update-indication-bit-position=-1
          signal VCU_EnergyCtrlMode: start 58, 1 bit, little-endian, init-value=0, base-type=uint8, implementation-data-type=DT_VCU_EnergyCtrlMode, update-indication-bit-position=-1
          signal VCU_VehSpdLimtRemind_ID514: start 59, 1 bit, little-endian, init-value=0, base-type=uint8, implementation-data-type=DT_VCU_VehSpdLimtRemind_ID514, update-indication-bit-position=-1
          signal VCU_TurtleLamp: start 60, 1 bit, little-endian, init-value=0, base-type=uint8, implementation-data-type=DT_VCU_TurtleLamp, update-indication-bit-position=-1
          signal VCU_EngLongTimeStartReq: start 61, 1 bit, little-endian, init-value=0, base-type=uint8, update-indication-bit-position=-1
      frame MCUM_0x605: id 0x605, from MVCU, frame-length=64, can-addressing-mode=STANDARD, can-fd-frame-support=true, can-frame-tx-behavior=CAN-FD
        carries pdu MCUM_0x605: packing-byte-order=little-endian, start-position=0, update-indication-bit-position=-1
        pdu MCUM_0x605: length=64, transmission-mode-false-timing=cyclic-timing={time-offset=0.0, time-period=0.2}, transmission-mode-true-timing=cyclic-timing={time-offset=0.0, time-period=0.2}
          transmission-mode-conditions:
            {data-filter={data-filter-type=ALWAYS, max=255, min=0, offset=0}, i-signal-in-i-pdu=MCUM_FaultData{0..8}}
            {data-filter={data-filter-type=ALWAYS, max=18446744073709551615, min=0, offset=0}, i-signal-in-i-pdu=MCUM_FaultData{9..14}}
            data-filter={data-filter-type=ALWAYS, max=18446744073709551615, min=0, offset=0}
          signal MCUM_FaultData0: start 0, 8 bit, little-endian, init-value=0, base-type=uint8, implementation-data-type=DT_MCUM_FaultData0, update-indication-bit-position=-1
          signal MCUM_FaultData1: start 8, 8 bit, little-endian, init-value=0, base-type=uint8, implementation-data-type=DT_MCUM_FaultData1, update-indication-bit-position=-1
          signal MCUM_FaultData2: start 16, 8 bit, little-endian, init-value=0, base-type=uint8, implementation-data-type=DT_MCUM_FaultData2, update-indication-bit-position=-1
          signal MCUM_FaultData3: start 24, 8 bit, little-endian, init-value=0, base-type=uint8, implementation-data-type=DT_MCUM_FaultData3, update-indication-bit-position=-1
          signal MCUM_FaultData4: start 32, 8 bit, little-endian, init-value=0, base-type=uint8, implementation-data-type=DT_MCUM_FaultData4, update-indication-bit-position=-1
          signal MCUM_FaultData5: start 40, 8 bit, little-endian, init-value=0, base-type=uint8, implementation-data-type=DT_MCUM_FaultData5, update-indication-bit-position=-1
          signal MCUM_FaultData6: start 48, 8 bit, little-endian, init-value=0, base-type=uint8, implementation-data-type=DT_MCUM_FaultData6, update-indication-bit-position=-1
          signal MCUM_FaultData7: start 56, 8 bit, little-endian, init-value=0, base-type=uint8, implementation-data-type=DT_MCUM_FaultData7, update-indication-bit-position=-1
          signal MCUM_FaultData8: start 64, 64 bit, little-endian, init-value=0, base-type=uint64, implementation-data-type=DT_MCUM_FaultData8, update-indication-bit-position=-1
          signal MCUM_FaultData9: start 128, 64 bit, little-endian, init-value=0, base-type=uint64, implementation-data-type=DT_MCUM_FaultData9, update-indication-bit-position=-1
          signal MCUM_FaultData10: start 192, 64 bit, little-endian, init-value=0, base-type=uint64, implementation-data-type=DT_MCUM_FaultData10, update-indication-bit-position=-1
          signal MCUM_FaultData11: start 256, 64 bit, little-endian, init-value=0, base-type=uint64, implementation-data-type=DT_MCUM_FaultData11, update-indication-bit-position=-1
          signal MCUM_FaultData12: start 320, 64 bit, little-endian, init-value=0, base-type=uint64, implementation-data-type=DT_MCUM_FaultData12, update-indication-bit-position=-1
          signal MCUM_FaultData13: start 384, 64 bit, little-endian, init-value=0, base-type=uint64, implementation-data-type=DT_MCUM_FaultData13, update-indication-bit-position=-1
          signal MCUM_FaultData14: start 448, 64 bit, little-endian, init-value=0, base-type=uint64, implementation-data-type=DT_MCUM_FaultData14, update-indication-bit-position=-1
      frame MCUM_0x607: id 0x607, from MVCU, frame-length=64, can-addressing-mode=STANDARD, can-fd-frame-support=true, can-frame-tx-behavior=CAN-FD
        carries pdu MCUM_0x607: packing-byte-order=little-endian, start-position=0, update-indication-bit-position=-1
        pdu MCUM_0x607: length=64, transmission-mode-false-timing=cyclic-timing={time-offset=0.0, time-period=0.2}, transmission-mode-true-timing=cyclic-timing={time-offset=0.0, time-period=0.2}
          transmission-mode-conditions:
            {data-filter={data-filter-type=ALWAYS, max=255, min=0, offset=0}, i-signal-in-i-pdu=MCUM_R_FaultData{0..8}}
            {data-filter={data-filter-type=ALWAYS, max=18446744073709551615, min=0, offset=0}, i-signal-in-i-pdu=MCUM_R_FaultData{9..14}}
            data-filter={data-filter-type=ALWAYS, max=18446744073709551615, min=0, offset=0}
          signal MCUM_R_FaultData0: start 0, 8 bit, little-endian, init-value=0, base-type=uint8, implementation-data-type=DT_MCUM_R_FaultData0, update-indication-bit-position=-1
          signal MCUM_R_FaultData1: start 8, 8 bit, little-endian, init-value=0, base-type=uint8, implementation-data-type=DT_MCUM_R_FaultData1, update-indication-bit-position=-1
          signal MCUM_R_FaultData2: start 16, 8 bit, little-endian, init-value=0, base-type=uint8, implementation-data-type=DT_MCUM_R_FaultData2, update-indication-bit-position=-1
          signal MCUM_R_FaultData3: start 24, 8 bit, little-endian, init-value=0, base-type=uint8, implementation-data-type=DT_MCUM_R_FaultData3, update-indication-bit-position=-1
          signal MCUM_R_FaultData4: start 32, 8 bit, little-endian, init-value=0, base-type=uint8, implementation-data-type=DT_MCUM_R_FaultData4, update-indication-bit-position=-1
          signal MCUM_R_FaultData5: start 40, 8 bit, little-endian, init-value=0, base-type=uint8, implementation-data-type=DT_MCUM_R_FaultData5, update-indication-bit-position=-1
          signal MCUM_R_FaultData6: start 48, 8 bit, little-endian, init-value=0, base-type=uint8, implementation-data-type=DT_MCUM_R_FaultData6, update-indication-bit-position=-1
          signal MCUM_R_FaultData7: start 56, 8 bit, little-endian, init-value=0, base-type=uint8, implementation-data-type=DT_MCUM_R_FaultData7, update-indication-bit-position=-1
          signal MCUM_R_FaultData8: start 64, 64 bit, little-endian, init-value=0, base-type=uint64, implementation-data-type=DT_MCUM_R_FaultData8, update-indication-bit-position=-1
          signal MCUM_R_FaultData9: start 128, 64 bit, little-endian, init-value=0, base-type=uint64, implementation-data-type=DT_MCUM_R_FaultData9, update-indication-bit-position=-1
          signal MCUM_R_FaultData10: start 192, 64 bit, little-endian, init-value=0, base-type=uint64, implementation-data-type=DT_MCUM_R_FaultData10, update-indication-bit-position=-1
          signal MCUM_R_FaultData11: start 256, 64 bit, little-endian, init-value=0, base-type=uint64, implementation-data-type=DT_MCUM_R_FaultData11, update-indication-bit-position=-1
          signal MCUM_R_FaultData12: start 320, 64 bit, little-endian, init-value=0, base-type=uint64, implementation-data-type=DT_MCUM_R_FaultData12, update-indication-bit-position=-1
          signal MCUM_R_FaultData13: start 384, 64 bit, little-endian, init-value=0, base-type=uint64, implementation-data-type=DT_MCUM_R_FaultData13, update-indication-bit-position=-1
          signal MCUM_R_FaultData14: start 448, 64 bit, little-endian, init-value=0, base-type=uint64, implementation-data-type=DT_MCUM_R_FaultData14, update-indication-bit-position=-1
      frame ECM_0x147: id 0x147, to MVCU, frame-length=32, can-addressing-mode=STANDARD, can-fd-frame-support=true, can-frame-rx-behavior=CAN-FD
        carries pdu ECM_0x147: packing-byte-order=little-endian, start-position=0, update-indication-bit-position=-1
        pdu ECM_0x147: length=32, transmission-mode-false-timing=cyclic-timing={time-offset=0.0, time-period=0.1}, transmission-mode-true-timing=cyclic-timing={time-offset=0.0, time-period=0.1}
          signal ECM_FuelConsumption: start 232, 8 bit, little-endian, init-value=0, base-type=uint8, update-indication-bit-position=-1, to MVCU
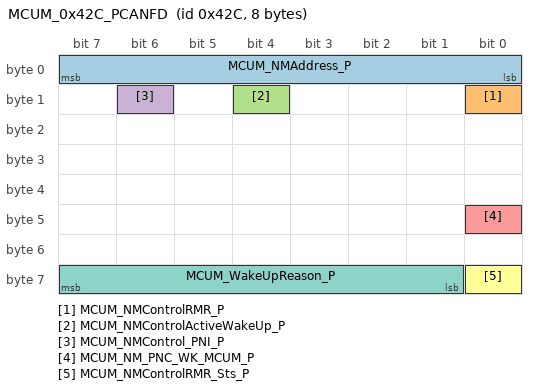
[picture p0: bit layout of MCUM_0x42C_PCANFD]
      frame MCUM_0x42C_PCANFD: id 0x42C, from MVCU, frame-length=8, can-addressing-mode=STANDARD, can-frame-tx-behavior=CAN-FD
        carries pdu MCUM_0x42C_PCANFD: packing-byte-order=little-endian, start-position=0, update-indication-bit-position=-1
        nm pdu MCUM_0x42C_PCANFD: length=8, nm-data-information=false, nm-vote-information=false
          signal MCUM_NMAddress_P: start 0, 8 bit, little-endian, base-type=uint8, update-indication-bit-position=-1
          signal MCUM_NMControlRMR_P: start 8, 1 bit, little-endian, base-type=uint8, update-indication-bit-position=-1
          signal MCUM_NMControlActiveWakeUp_P: start 12, 1 bit, little-endian, base-type=uint8, update-indication-bit-position=-1
          signal MCUM_NMControl_PNI_P: start 14, 1 bit, little-endian, base-type=uint8, update-indication-bit-position=-1
          signal MCUM_NM_PNC_WK_MCUM_P: start 40, 1 bit, little-endian, base-type=uint8, update-indication-bit-position=-1
          signal MCUM_NMControlRMR_Sts_P: start 56, 1 bit, little-endian, init-value=NumericalValueSpecification_0:0, base-type=uint8, implementation-data-type=DT_MCUM_NMControlRMR_Sts_P, update-indication-bit-position=-1
          signal MCUM_WakeUpReason_P: start 57, 7 bit, little-endian, init-value=NumericalValueSpecification_0:0, base-type=uint8, implementation-data-type=DT_MCUM_WakeUpReason_P, update-indication-bit-position=-1
package /DBC_SysDesc_P_CANFD/Pkg_Nm
  nm config NmConfig_0
    can nm cluster CanNmCluster_0: communication-cluster=P_CANFD, nm-channel-id=1, nm-channel-sleep-master=false, nm-synchronizing-network=false, nm-busload-reduction-active=false, nm-car-wake-up-filter-enabled=false, nm-car-wake-up-rx-enabled=false, nm-channel-active=false
      can nm node CanNmMode_MVCU_P_CANFD: controller=P_CANFD, nm-if-ecu=NmEcu_MVCU, nm-node-id=1, nm-passive-mode-enabled=false, rx-nm-pdu=HPCBCM_0x401, tx-nm-pdu=MCUM_0x42C, nm-range-config={lower-can-id=1025, upper-can-id=1068}
    nm-if-ecus:
      nm ecu NmEcu_MVCU:
        bus-specific-nm-ecu=can-nm-ecu=nm-repeat-msg-indication-enabled=false
        ecu-instance=MVCU
        nm-bus-synchronization-enabled=false
        nm-com-control-enabled=false
        nm-coordinator=nm-node=CanNmMode_MVCU_P_CANFD
        nm-multiple-channels-enabled=false
        nm-node-detection-enabled=false
        nm-node-id-enabled=false
        nm-passive-mode-enabled=false
        nm-pdu-rx-indication-enabled=false
        nm-remote-sleep-ind-enabled=false
        nm-repeat-msg-ind-enabled=false
        nm-state-change-ind-enabled=false
        nm-user-data-enabled=false
package /DBC_SysDesc_P_CANFD/Pkg_Ecu
  ecu instance MVCU: com-configuration-gw-time-base=0.005, com-configuration-rx-time-base=0.01, com-configuration-tx-time-base=0.01, sleep-mode-supported=false, wake-up-over-bus-supported=false
    can communication controller P_CANFD: can-controller-attributes=can-controller-configuration={can-controller-fd-requirements={max-sample-point=81.4, tx-bit-rate-switch=false}, prop-seg=0, sync-jump-width=0, time-seg-1=10, time-seg-2=0}
    can communication controller C_CANFD: can-controller-attributes=can-controller-configuration={can-controller-fd-requirements={max-sample-point=81.4, tx-bit-rate-switch=false}, prop-seg=0, sync-jump-width=0, time-seg-1=10, time-seg-2=0}
    can communication controller VCU_CAN: can-controller-attributes=can-controller-configuration={prop-seg=0, sync-jump-width=0, time-seg-1=10, time-seg-2=0}
    can communication connector Conn_P_CANFD_MVCU: comm-controller=P_CANFD
    can communication connector Conn_C_CANFD_MVCU: comm-controller=C_CANFD
    can communication connector Conn_VCU_CAN_MVCU: comm-controller=VCU_CAN
package /DBC_SysDesc_P_CANFD/Pkg_CompuMethod
  compu method CompuMethod_CCM_RollingCounter_36A: raw=phys for phys 0..15
  compu method CompuMethod_CCM_BaseState: raw=phys for phys 0..7
  compu method CompuMethod_CCM_Power: raw=phys*20 for phys 0..12
  compu method CompuMethod_CCM_APTC_BscSts: raw=phys for phys 0..1
  compu method CompuMethod_GW_BZCU_Cab_PDU220VRelay_CtrlSts: raw=phys for phys 0..1
  compu method CompuMethod_VCU_IVI_RecvTr: raw=phys for phys 0..1
  compu method CompuMethod_GW_BZCU_FuelTankSts: raw=phys for phys 0..1
  compu method CompuMethod_VCU_DriveMHVILSts: raw=phys for phys 0..1
  compu method CompuMethod_ECM_ToothlearningSucValid: raw=phys for phys 0..3
  compu method CompuMethod_ECM_EngineSpeedValid: raw=phys for phys 0..1
  compu method CompuMethod_Debug_MCU_DrvMotorRPMVD: raw=phys for phys 0..1
  compu method CompuMethod_HPCBCM_NMControl_PNI: raw=phys for phys 0..1
  compu method CompuMethod_MCUM_UDS_Boot8: raw=phys for phys 0..255
  compu method CompuMethod_OBC_RollingCounter_316: raw=phys for phys 0..15
  compu method CompuMethod_VCU_MGCUWorkMode: raw=phys for phys 0..3
  compu method CompuMethod_MCUM_FaultData27: raw=phys for phys 0..255
  compu method CompuMethod_VCU_MotSelfHeatPwrFb: raw=phys for phys 0..31
  compu method CompuMethod_VCU_WheelTrqType: raw=phys for phys 0..15
  compu method CompuMethod_MCUM_NMControlActiveWakeUp: raw=phys for phys 0..1
  compu method CompuMethod_VCU_VehicleHighVoltModeF: raw=phys for phys 0..7
  compu method CompuMethod_VCU_EngineFuleCutoffReq: raw=phys for phys 0..1
  compu method CompuMethod_VCU_BrakePedalStsValid_P: raw=phys for phys 0..1
  compu method CompuMethod_MCUM_UDS_SW9: raw=phys for phys 0..255
  compu method CompuMethod_MCUM_TMS_MotSelfHeatLvlFb: raw=phys for phys 0..7
  compu method CompuMethod_GainIden_Is_Samp_U: raw=phys*10 for phys 0..1000
  compu method CompuMethod_MCUM_SBC_InsideVotageFault: raw=phys for phys 0..1
  compu method CompuMethod_GW_CRC_3B1: raw=phys for phys 0..255
  compu method CompuMethod_MCUM_FaultData62: raw=phys for phys 0..255
  compu method CompuMethod_BCM_VCU_Authentication_MAC_B2: raw=phys for phys 0..255
  compu method CompuMethod_MCUM_FaultData0: raw=phys for phys 0..255
  compu method CompuMethod_MotClb_FaultCode8: raw=phys for phys 0..255
  compu method CompuMethod_EOL_PosDly_SnsrSupplier: raw=phys for phys 0..1
  compu method CompuMethod_VCU_EolCfg_RudderDir: raw=phys for phys 0..1
  compu method CompuMethod_VCU_PowerModeSwitchMsg: raw=phys for phys 0..1
  compu method CompuMethod_MotClb_IqSet: raw=phys*10+10000 for phys -1000..1000
  compu method CompuMethod_Debug_MCU_DrvMotorRPM: raw=phys+17000 for phys -17000..30000
  compu method CompuMethod_DCDC_Real_Output_Current: raw=phys*10 for phys 0..250
  compu method CompuMethod_VCU_HighPerforSwtFlg: raw=phys for phys 0..1
  compu method CompuMethod_GCU_MaxTorque: raw=phys*10+2000 for phys -200..200
  compu method CompuMethod_VCU_CRC_13B: raw=phys for phys 0..255
  compu method CompuMethod_GW_TCM_GearLevelSwitchSts: raw=phys for phys 0..7
  compu method CompuMethod_BMS_BattSOC_Display: raw=phys*10 for phys 0..100
  compu method CompuMethod_EOL_ON2BRelayReq: raw=phys for phys 0..3
  compu method CompuMethod_GW_BZCU_DCChgExitTemp_Pos: raw=phys+40 for phys -40..210
  compu method CompuMethod_MCUM_FaultData32: raw=phys for phys 0..255
  compu method CompuMethod_IVI_Month: raw=phys for phys 0..12
  compu method CompuMethod_VCU_SpdLimModeSts: raw=phys for phys 0..3
  compu method CompuMethod_MCUM_UDS_ProductModel10: raw=phys for phys 0..255
  compu method CompuMethod_MCUM_HeatPwrAval: raw=phys for phys 0..31
  compu method CompuMethod_GW_TCM_STATUS_RND: raw=phys for phys 0..1
  compu method CompuMethod_VCU_BMSMainRelayF_Cmd: raw=phys for phys 0..1
  compu method CompuMethod_VCU_LVSystemError: raw=phys for phys 0..1
  compu method CompuMethod_VCU_SlopeEst: raw=phys*2+200 for phys -100..100
  compu method CompuMethod_OfsIden_IFStart_Overtime: raw=phys for phys 0..1
  compu method CompuMethod_MCUM_FaultData40: raw=phys for phys 0..255
  compu method CompuMethod_VCU_BMS_RecvTr: raw=phys for phys 0..1
  compu method CompuMethod_VCU_DriverAssistProhibitSts_ID514: raw=phys for phys 0..1
  compu method CompuMethod_MCUS_DrvMotorWorkSts: raw=phys for phys 0..3
  compu method CompuMethod_VCU_FTorqueSwFb: raw=phys for phys 0..1
  compu method CompuMethod_VCU_BrakeSwitchSts: raw=phys for phys 0..3
  compu method CompuMethod_ECM_EngineOilPressureLow: raw=phys for phys 0..1
  compu method CompuMethod_Debug_MCUM_TMS_MotSelfHeatLvlFb: raw=phys for phys 0..7
  compu method CompuMethod_MotClb_IsCMD_Fb: raw=phys*10+10000 for phys -1000..1000
  compu method CompuMethod_VCU_InterAllowEngStart: raw=phys for phys 0..1
  compu method CompuMethod_MCUM_5msOverTime_Cnt: raw=phys for phys 0..15
  compu method CompuMethod_GTC_ThetaDelt: raw=phys*100 for phys 0..360
  compu method CompuMethod_MCUM_IGBTTemp_U: raw=phys+50 for phys -50..200
  compu method CompuMethod_VCU_EolCfg_APS: raw=phys for phys 0..1
  compu method CompuMethod_S16_CMD4: raw=phys+32768 for phys -32768..32767
  compu method CompuMethod_BCM_KeyPosition_ON2B: raw=phys for phys 0..1
  compu method CompuMethod_BCM_NM_PNC_ON_3Ch_Sts: raw=phys for phys 0..1
  compu method CompuMethod_BCM_HighVoltageReq: raw=phys+3 for phys 0..1
  compu method CompuMethod_IVI_ShowCarModeReq: raw=phys for phys 0..3
  compu method CompuMethod_BCM_FRDoorSts: raw=phys for phys 0..1
  compu method CompuMethod_MCUM_12V_Max: raw=phys for phys 0..255
  compu method CompuMethod_BMS_MODE_t: raw=phys for phys 0..15
  compu method CompuMethod_GW_IBC_FRWheelDirection: raw=phys for phys 0..3
  compu method CompuMethod_MCUM_HWRdc_RstCnt: raw=phys for phys 0..15
  compu method CompuMethod_MCUM_RawCosCorr: raw=phys+2000 for phys -2000..2000
  compu method CompuMethod_ECM_EngineFuleCutoffSts: raw=phys for phys 0..1
  compu method CompuMethod_BMS_PreHeatingState: raw=phys for phys 0..3
  compu method CompuMethod_VCU_FaultData7: raw=phys for phys 0..255
  compu method CompuMethod_ICU_Switch_CLTCOrWLTC: raw=phys for phys 0..7
  compu method CompuMethod_EVCC_EVSEMaximumCurrentLimit: raw=phys for phys 0..254
  compu method CompuMethod_Debug_MCU_DCChargRelaySts: raw=phys for phys 0..1
  compu method CompuMethod_EddyCur_FauPro_SpdInstab_Flag: raw=phys for phys 0..1
  compu method CompuMethod_Debug_MCU_ActualTorqueFB: raw=phys*10+5000 for phys -500..500
  compu method CompuMethod_PosDly_Theta_k_Std: raw=phys*1000000+10000 for phys -0.01..0.01
  compu method CompuMethod_MCUM_Damp_State: raw=phys for phys 0..1
  compu method CompuMethod_VCU_PTC_RecvTr: raw=phys for phys 0..1
  compu method CompuMethod_VCU_BCM_Authentication_MAC_A4: raw=phys for phys 0..255
  compu method CompuMethod_U8_CMD2: raw=phys for phys 0..255
  compu method CompuMethod_VCU_SuppressJitterMCUMRequest: raw=phys for phys 0..1
  compu method CompuMethod_VCU_BCM_Authentication_MAC_A14: raw=phys for phys 0..255
  compu method CompuMethod_BCM_CcmHvilSts_ID291: raw=phys for phys 0..1
  compu method CompuMethod_GainIden_Is_Samp_W: raw=phys*10 for phys 0..1000
  compu method CompuMethod_BMS_DCChgHVILSts: raw=phys for phys 0..1
  compu method CompuMethod_MCUM_FaultData49: raw=phys for phys 0..255
  compu method CompuMethod_MCUM_HWFoB_RstCnt: raw=phys for phys 0..15
  compu method CompuMethod_BCM_PDUHVIL_STs: raw=phys for phys 0..1
  compu method CompuMethod_Debug_MCU_MaxTorqueAllow: raw=phys*10+5000 for phys -500..500
  compu method CompuMethod_ECM_FuelLevel: raw=phys*10 for phys 0..100
  compu method CompuMethod_VCU_EolCfg_ESC: raw=phys for phys 0..1
  compu method CompuMethod_VCU_IMMOKeyWriteCnt: raw=phys for phys 0..7
  compu method CompuMethod_VCU_AbStartupFlag: raw=phys for phys 0..1
  compu method CompuMethod_VCU_AbResetFlag: raw=phys for phys 0..1
  compu method CompuMethod_VCU_AbResetlnitFinish: raw=phys for phys 0..1
  compu method CompuMethod_IVI_Hour: raw=phys for phys 0..23
  compu method CompuMethod_DCDC_Real_Output_Voltage: raw=phys*10 for phys 0..50
  compu method CompuMethod_BCM_ON2CRelaySts: raw=phys for phys 0..1
  compu method CompuMethod_GCU_MAXPower: raw=phys for phys 0..250
  compu method CompuMethod_ECM_GPFRegenlamp: raw=phys for phys 0..3
  compu method CompuMethod_VCU_EngineSts: raw=phys for phys 0..15
  compu method CompuMethod_VCU_MCUMMaxChargePower: raw=phys for phys 0..510
  compu method CompuMethod_MCUM_EOP_IqRef: raw=phys*10 for phys 0..50
  compu method CompuMethod_PosDly_FauPro_SpdUp_OTm_Flag: raw=phys for phys 0..1
  compu method CompuMethod_VCU_GearBeforDriving: raw=phys for phys 0..1
  compu method CompuMethod_HPCBCM_NM_PNC26: raw=phys for phys 0..1
  compu method CompuMethod_OfsIden_IdenCntOver: raw=phys for phys 0..1
  compu method CompuMethod_VCU_TCM_RecvTr: raw=phys for phys 0..1
  compu method CompuMethod_GCU_ActualMotorRPM_VD: raw=phys for phys 0..1
  compu method CompuMethod_GCU_HVOffReq: raw=phys for phys 0..1
  compu method CompuMethod_GW_IBC_RLWheelSpeedVD: raw=phys for phys 0..1
  compu method CompuMethod_MCUM_UDS_SW8: raw=phys for phys 0..255
  compu method CompuMethod_MCUM_FaultData13: raw=phys for phys 0..255
  compu method CompuMethod_GW_IBC_VehicleSpeedVD: raw=phys for phys 0..1
  compu method CompuMethod_GainIden_Iden_Finish: raw=phys for phys 0..1
  compu method CompuMethod_VCU_CheckSum_BB: raw=phys for phys 0..255
  compu method CompuMethod_VCU_WorkModeReq_PHEV: raw=phys for phys 0..7
  compu method CompuMethod_VCU_WorkMode_PHEV: raw=phys for phys 0..7
  compu method CompuMethod_VCU_HEVAllow_PHEV: raw=phys for phys 0..1
  compu method CompuMethod_VCU_REAllow_PHEV: raw=phys for phys 0..1
  compu method CompuMethod_VCU_EVDualAllow_PHEV: raw=phys for phys 0..1
  compu method CompuMethod_VCU_EVSingleAllow_PHEV: raw=phys for phys 0..1
  compu method CompuMethod_VCU_Clutch_2_RequesSpeed: raw=phys for phys 0..65535
  compu method CompuMethod_VCU_Clutch_1_RequesSpeed: raw=phys for phys 0..65535
  compu method CompuMethod_VCU_Clutch2Position: raw=phys for phys 0..3
  compu method CompuMethod_VCU_Clutch1Position: raw=phys for phys 0..3
  compu method CompuMethod_MCUM_SBC_TempOverFault: raw=phys for phys 0..1
  compu method CompuMethod_Harness_KeyON: raw=phys for phys 0..1
  compu method CompuMethod_BCM_ChargeLockCtrl: raw=phys for phys 0..3
  compu method CompuMethod_BCM_VCU_Authentication_Sts: raw=phys for phys 0..3
  compu method CompuMethod_VCU_EolCfg_WheelType: raw=phys for phys 0..15
  compu method CompuMethod_BMS_InverterRequest: raw=phys for phys 0..1
  compu method CompuMethod_MCUS_HeatPwrAval: raw=phys for phys 0..31
  compu method CompuMethod_ECM_UDS_Res_Byte4: raw=phys for phys 0..1
  compu method CompuMethod_MCUM_FaultData22: raw=phys for phys 0..255
  compu method CompuMethod_Debug_MCU_PowerReduceSts: raw=phys for phys 0..1
  compu method CompuMethod_MCUM_FaultData17: raw=phys for phys 0..255
  compu method CompuMethod_GW_IBC_FLWheelSpeedKPH: raw=phys*100 for phys 0..450
  compu method CompuMethod_CDU_OBC_OverTemp: raw=phys for phys 0..1
  compu method CompuMethod_VCU_GCU_RecvTr: raw=phys for phys 0..1
  compu method CompuMethod_MCUS_ActiveReleaseSts: raw=phys for phys 0..3
  compu method CompuMethod_EOL_RDrvRequesSpeedVD: raw=phys for phys 0..1
  compu method CompuMethod_VCU_MCUMActiveReleaseCmd: raw=phys for phys 0..1
  compu method CompuMethod_IVI_Year: raw=phys for phys 0..4094
  compu method CompuMethod_VCU_HighVoltSysSts: raw=phys for phys 0..15
  compu method CompuMethod_MCUM_FaultData1: raw=phys for phys 0..255
  compu method CompuMethod_GW_TCM_RollingCounter_30B: raw=phys for phys 0..15
  compu method CompuMethod_VCU_SystemError: raw=phys for phys 0..1
  compu method CompuMethod_BCM_VCU_Authentication_MAC_B9: raw=phys for phys 0..255
  compu method CompuMethod_MCUM_RDC_Reset_Count: raw=phys for phys 0..255
  compu method CompuMethod_BMS_DCChgRelayFB: raw=phys for phys 0..1
  compu method CompuMethod_BMS_SelfCheck: raw=phys for phys 0..2
  compu method CompuMethod_MCUM_NVM_VehicleTypeRFault: raw=phys for phys 0..1
  compu method CompuMethod_ECM_IdleTargetSpeed: raw=phys for phys 0..4094
  compu method CompuMethod_MCUM_CpldRest_ASC_Flag: raw=phys for phys 0..1
  compu method CompuMethod_VCU_VehPwrChageLimit: raw=phys for phys 0..250
  compu method CompuMethod_GainIden_Rslt_U: raw=phys*1000-700 for phys 0.7..1.2
  compu method CompuMethod_MotClb_Iq_Fb: raw=phys*10+10000 for phys -1000..1000
  compu method CompuMethod_BMS_StateOfEngeryMax: raw=phys*0.1 for phys 0..655300
  compu method CompuMethod_MCUM_UDS_ProductModel13: raw=phys for phys 0..255
  compu method CompuMethod_MCUM_FaultData45: raw=phys for phys 0..255
  compu method CompuMethod_VCU_Vehicle_NVHPwrLimitVal: raw=phys for phys 0..250
  compu method CompuMethod_EOL_RMCUMaxChargePower: raw=phys for phys 0..510
  compu method CompuMethod_VCU_EngineStopAllow: raw=phys for phys 0..1
  compu method CompuMethod_BMS_RNegativeRelay_F: raw=phys for phys 0..1
  compu method CompuMethod_OfsIden_ZeroAlign_Fail: raw=phys for phys 0..1
  compu method CompuMethod_VCU_VehSpdLimtRemind: raw=phys for phys 0..1
  compu method CompuMethod_MCUM_NVM_RslvrZeroRFault: raw=phys for phys 0..1
  compu method CompuMethod_MCUM_Iq_Fb: raw=phys+1000 for phys -1000..1000
  compu method CompuMethod_Harness_CoolWaterTemp: raw=phys+50 for phys -50..205
  compu method CompuMethod_GW_TCM_STATUS_Park: raw=phys for phys 0..1
  compu method CompuMethod_PosDly_FauPro_Check_Divergence: raw=phys for phys 0..1
  compu method CompuMethod_BMS_BattChargerSts: raw=phys for phys 0..7
  compu method CompuMethod_VCU_EngineOffRequest: raw=phys for phys 0..1
  compu method CompuMethod_GW_IBC_AVHStatus: raw=phys for phys 0..3
  compu method CompuMethod_VCU_MCUSDiffProtectSts: raw=phys for phys 0..1
  compu method CompuMethod_GW_CRC_13A: raw=phys for phys 0..255
  compu method CompuMethod_PosDly_Supplier: raw=phys for phys 0..1
  compu method CompuMethod_GW_TCM_CRC_RND: raw=phys for phys 0..255
  compu method CompuMethod_MCUS_CtrlMode: raw=phys for phys 0..1
  compu method CompuMethod_Harness_I_U: raw=phys*20.48001049 for phys 0..12.4512
  compu method CompuMethod_VCU_MCUSMaxPosDampgTrq: raw=phys for phys 0..50
  compu method CompuMethod_VCU_REStartReq: raw=phys for phys 0..1
  compu method CompuMethod_GW_BZCU_Cabin_220VRelay_CtrlSts: raw=phys for phys 0..1
  compu method CompuMethod_VCU_VehicleSts: raw=phys for phys 0..1
  compu method CompuMethod_MCUM_FaultData26: raw=phys for phys 0..255
  compu method CompuMethod_Debug_MCU_CtrlMode: raw=phys for phys 0..1
  compu method CompuMethod_GainIden_Write_Finish: raw=phys for phys 0..1
  compu method CompuMethod_VCU_MotSelfHeatAllwd: raw=phys for phys 0..1
  compu method CompuMethod_VCU_Comfirmed_DTC: raw=phys for phys 0..254
  compu method CompuMethod_MCUM_FaultData47: raw=phys for phys 0..255
  compu method CompuMethod_VCU_DIn_BrkPedClose: raw=phys for phys 0..1
  compu method CompuMethod_IVI_InventerLimitOdometerkmVD: raw=phys for phys 0..1
  compu method CompuMethod_GCU_MILlampReq: raw=phys for phys 0..1
  compu method CompuMethod_OfsIden_OfsWrite_Finish: raw=phys for phys 0..1
  compu method CompuMethod_MCUM_FaultData4: raw=phys for phys 0..255
  compu method CompuMethod_ECM_UDS_PhyReq_Byte6: raw=phys for phys 0..1
  compu method CompuMethod_BMS_HVPackPosRelayExternalVolt: raw=phys*2 for phys 0..1000
  compu method CompuMethod_MCUS_MaxSpeedAllow: raw=phys+17000 for phys -17000..17000
  compu method CompuMethod_GW_BZCU_Cab_220Vconnect_Sts: raw=phys for phys 0..1
  compu method CompuMethod_VCU_MCUSMaxNegDampgTrq: raw=phys+50 for phys -50..0
  compu method CompuMethod_DelayIden_Rslt_V: raw=phys for phys 0..5000
  compu method CompuMethod_VCU_SDrvControlModeVD: raw=phys for phys 0..1
  compu method CompuMethod_VCU_Pending_DTC: raw=phys for phys 0..254
  compu method CompuMethod_VCU_FaultData10: raw=phys for phys 0..255
  compu method CompuMethod_MCUM_12V_Min: raw=phys*10 for phys 0..20
  compu method CompuMethod_TMS_MCUMHeatPwrReq: raw=phys*0.01 for phys 0..12800
  compu method CompuMethod_MCUM_HWOV_RstCnt: raw=phys for phys 0..15
  compu method CompuMethod_MCUM_UDS_HW7: raw=phys for phys 0..255
  compu method CompuMethod_MCUM_FaultData50: raw=phys for phys 0..255
  compu method CompuMethod_VCU_CalibrationVersion: raw=phys for phys 0..15
  compu method CompuMethod_MotClb_ThetaCMD_Fb: raw=phys*10+10000 for phys -1000..1000
  compu method CompuMethod_MCUM_Fault_DCChargRelay: raw=phys for phys 0..1
  compu method CompuMethod_Debug_MCU_MILlampReq: raw=phys for phys 0..1
  compu method CompuMethod_MotClb_FaultCode1: raw=phys for phys 0..255
  compu method CompuMethod_MCUS_DrvMotorRPMVD: raw=phys for phys 0..1
  compu method CompuMethod_MotClb_UqFb: raw=phys*10+10000 for phys -1000..1000
  compu method CompuMethod_VCU_VehicleSpdDirect: raw=phys+255 for phys -255..255
  compu method CompuMethod_VCU_ADM_ActualMode: raw=phys+255 for phys -255..3
  compu method CompuMethod_VCU_ADM_MainMode: raw=phys+255 for phys -255..3
  compu method CompuMethod_CDU_HV_HIVSts: raw=phys for phys 0..1
  compu method CompuMethod_VCU_FuelDetctionModule: raw=phys for phys 0..1
  compu method CompuMethod_GW_BZCU_ACChgExitTemp_Neg: raw=phys+40 for phys -40..210
  compu method CompuMethod_VCU_RollingCounter_13B: raw=phys for phys 0..15
  compu method CompuMethod_ICU_WLTC_ElectticityMileage: raw=phys for phys 0..2000
  compu method CompuMethod_VCU_GearLvrChangeSts: raw=phys for phys 0..15
  compu method CompuMethod_EOL_ModeCMD_Data3: raw=phys for phys 0..255
  compu method CompuMethod_EOL_RMCUActiveReleaseCmd: raw=phys for phys 0..1
  compu method CompuMethod_HPCBCM_NMControlRMR: raw=phys for phys 0..1
  compu method CompuMethod_EMS_EngineSts: raw=phys for phys 0..7
  compu method CompuMethod_Debug_MCU_MainWireVolt: raw=phys*10 for phys 0..1000
  compu method CompuMethod_MCUM_LimSpdTorFlag: raw=phys for phys 0..1
  compu method CompuMethod_VCU_VacumRlySts: raw=phys for phys 0..1
  compu method CompuMethod_VCU_PwnIn_CcmHvilFreqFb: raw=phys for phys 0..100
  compu method CompuMethod_MCUM_FaultData23: raw=phys for phys 0..255
  compu method CompuMethod_MCUM_UDS_HW6: raw=phys for phys 0..255
  compu method CompuMethod_EOL_AccPedalValid: raw=phys for phys 0..1
  compu method CompuMethod_BMS_InverterPower: raw=phys*10 for phys 0..25
  compu method CompuMethod_VCU_Pwr_LossFctorFlg: raw=phys for phys 0..1
  compu method CompuMethod_VCU_ParkBeforeFuelup: raw=phys for phys 0..1
  compu method CompuMethod_VCU_BrakeSysFault: raw=phys for phys 0..1
  compu method CompuMethod_MCUM_EOP_BlockErr_IsLim_Flag: raw=phys for phys 0..1
  compu method CompuMethod_GW_RollingCounter_13A: raw=phys for phys 0..15
  compu method CompuMethod_VCU_MMErrorSts: raw=phys for phys 0..1
  compu method CompuMethod_PTC_HV_interlock_faultSt: raw=phys for phys 0..1
  compu method CompuMethod_GW_ACU_FLSeatBeltRSt: raw=phys for phys 0..3
  compu method CompuMethod_VCU_SVehicleSts: raw=phys for phys 0..1
  compu method CompuMethod_BCM_DCChrgPwr_Sts_ID291: raw=phys for phys 0..1
  compu method CompuMethod_MCUM_StatorTemp_2: raw=phys+50 for phys -50..200
  compu method CompuMethod_VCU_REsystemFaultSts_ID514: raw=phys for phys 0..1
  compu method CompuMethod_MCUM_FaultData46: raw=phys for phys 0..255
  compu method CompuMethod_ECM_UDS_PhyReq_Byte7: raw=phys for phys 0..1
  compu method CompuMethod_GCU_SWVersionA: raw=phys for phys 0..15
  compu method CompuMethod_GW_TCM_SelfCheckSt: raw=phys for phys 0..1
  compu method CompuMethod_MCUM_UserDefine_Byte1: raw=phys for phys 0..255
  compu method CompuMethod_VCU_SDrvRequesSpeedVD: raw=phys for phys 0..1
  compu method CompuMethod_BMS_BattVolt: raw=phys*10 for phys 0..1000
  compu method CompuMethod_Debug_MCUM_MinTorqueAllow: raw=phys*10+5000 for phys -500..500
  compu method CompuMethod_ICU_EnergyRecoveryMode: raw=phys for phys 0..3
  compu method CompuMethod_U8_CMD8: raw=phys for phys 0..255
  compu method CompuMethod_ECM_UDS_PhyReq_Byte0: raw=phys for phys 0..1
  compu method CompuMethod_GCU_ActualMotorTorque_VD: raw=phys for phys 0..1
  compu method CompuMethod_MCUM_UDS_ProductModel16: raw=phys for phys 0..255
  compu method CompuMethod_VCU_BrakeBeforeGear: raw=phys for phys 0..1
  compu method CompuMethod_ECM_UDS_PhyReq_Byte5: raw=phys for phys 0..1
  compu method CompuMethod_EOL_MotClb_ThetaCMD: raw=phys*10+10000 for phys -1000..5553.5
  compu method CompuMethod_VCU_ACPwrLimited: raw=phys*10 for phys 0..25.5
  compu method CompuMethod_MCUM_Power_12V: raw=phys*10 for phys 0..25
  compu method CompuMethod_IVI_EngineIdlingMode: raw=phys for phys 0..1
  compu method CompuMethod_VCU_HVSystemError: raw=phys for phys 0..1
  compu method CompuMethod_EddyCur_Para_Sin_Pha: raw=phys*10000+20000 for phys -2..2
  compu method CompuMethod_TMS_RollingCounter_363: raw=phys for phys 0..15
  compu method CompuMethod_TMS_AC_Command: raw=phys for phys 0..1
  compu method CompuMethod_TMS_RAPTC_ModOprtgStsFrt: raw=phys for phys 0..1
  compu method CompuMethod_TMS_RAPTC_ModOpEnblCmd: raw=phys for phys 0..1
  compu method CompuMethod_TMS_RAPTC_MsrdPwrFrt: raw=phys for phys 0..1023
  compu method CompuMethod_EddyCur_FauPro_IDEL_OTime_Flag: raw=phys for phys 0..1
  compu method CompuMethod_VCU_VehicleDirectS: raw=phys for phys 0..1
  compu method CompuMethod_MCUM_MainWireVolt: raw=phys*10 for phys 0..1000
  compu method CompuMethod_BMS_MaxPower: raw=phys*20 for phys 0..25
  compu method CompuMethod_GTC_ThetaPos: raw=phys*100 for phys 0..360
  compu method CompuMethod_VCU_BCM_Authentication_MAC_A1: raw=phys for phys 0..255
  compu method CompuMethod_BMS_DCChgRelayCloseReq: raw=phys for phys 0..1
  compu method CompuMethod_MCUM_UDS_Supplier1: raw=phys for phys 0..255
  compu method CompuMethod_GW_TCM_Counter_Park: raw=phys for phys 0..15
  compu method CompuMethod_BMS_CCMHVILSts: raw=phys for phys 0..1
  compu method CompuMethod_VCU_STorqueReqValid: raw=phys for phys 0..1
  compu method CompuMethod_MCUM_FaultData59: raw=phys for phys 0..255
  compu method CompuMethod_MotClb_OfsAdjEn: raw=phys for phys 0..1
  compu method CompuMethod_BMS_SeriousWarning_Level: raw=phys for phys 0..3
  compu method CompuMethod_ICU_AccelerationMode: raw=phys for phys 0..7
  compu method CompuMethod_ECM_CalculatedLoad: raw=phys*10 for phys 0..100
  compu method CompuMethod_ECM_ClearingSparkcarbonedRequest: raw=phys*10 for phys 0..3
  compu method CompuMethod_MCUM_NVM_HallDelayRFault: raw=phys for phys 0..1
  compu method CompuMethod_EddyCur_Write_Flag: raw=phys for phys 0..1
  compu method CompuMethod_GCU_ActualMotorRPM: raw=phys+17000 for phys -17000..30000
  compu method CompuMethod_VCU_EolCfg_Curise: raw=phys for phys 0..3
  compu method CompuMethod_VCU_HVILSysSts: raw=phys for phys 0..15
  compu method CompuMethod_BMS_RPreChargeRelayFB: raw=phys for phys 0..1
  compu method CompuMethod_MCUM_SystemError: raw=phys for phys 0..1
  compu method CompuMethod_MCUM_Vd_Ref: raw=phys*0.5+500 for phys -1000..1000
  compu method CompuMethod_MCUM_MotorTemp: raw=phys+50 for phys -50..200
  compu method CompuMethod_MCUM_NMAddress: raw=phys for phys 0..255
  compu method CompuMethod_MCUM_UDS_ProductModel8: raw=phys for phys 0..255
  compu method CompuMethod_EMS_RollingCounter_BE: raw=phys for phys 0..15
  compu method CompuMethod_MCUM_Damp_CompCoeff: raw=phys*100 for phys 0..1
  compu method CompuMethod_MCUM_SBC_OutPutVotageFault: raw=phys for phys 0..1
  compu method CompuMethod_GW_IBC_RLWheelDirection: raw=phys for phys 0..3
  compu method CompuMethod_EOL_RDrvRequestTorqueVD: raw=phys for phys 0..1
  compu method CompuMethod_MCUS_PowerReduceSts: raw=phys for phys 0..1
  compu method CompuMethod_PTC_Power: raw=phys*0.02 for phys 0..10000
  compu method CompuMethod_EOL_MotClb_CtrlMode: raw=phys for phys 0..15
  compu method CompuMethod_EOL_MCUMMaxNegDampgTrq: raw=phys+50 for phys -50..0
  compu method CompuMethod_VCU_REOverChgPwrFlag: raw=phys for phys 0..1
  compu method CompuMethod_MCUM_UDS_ProductModel9: raw=phys for phys 0..255
  compu method CompuMethod_ECM_EngineStopAllow: raw=phys for phys 0..1
  compu method CompuMethod_GW_IBC_FRWheelSpeedVD: raw=phys for phys 0..1
  compu method CompuMethod_VCU_REChgTarget: raw=phys for phys 0..100
  compu method CompuMethod_MCUM_FaultData44: raw=phys for phys 0..255
  compu method CompuMethod_BCM_VCU_Authentication_MAC_B12: raw=phys for phys 0..255
  compu method CompuMethod_MCUM_JuncLoss_Max: raw=phys for phys 0..8000
  compu method CompuMethod_DCDC_Real_Input_Voltage: raw=phys*5 for phys 0..1000
  compu method CompuMethod_MCUM_FaultData48: raw=phys for phys 0..255
  compu method CompuMethod_GW_IBC_PlungerPressure: raw=phys*8 for phys 0..255.75
  compu method CompuMethod_ECM_EngineTorqueMax: raw=phys*2+1000 for phys -500..1547
  compu method CompuMethod_VCU_PwrReqByTqr: raw=phys for phys 0..250
  compu method CompuMethod_MCUM_FaultData25: raw=phys for phys 0..255
  compu method CompuMethod_VCU_FastPwrRequest: raw=phys for phys 0..250
  compu method CompuMethod_BCM_ACChrgPwr_Sts_ID291: raw=phys for phys 0..1
  compu method CompuMethod_MCUM_EOP_State: raw=phys for phys 0..15
  compu method CompuMethod_GW_TCM_CRC_Park: raw=phys for phys 0..255
  compu method CompuMethod_EVCC_DCAC_ChgMode: raw=phys for phys 0..14
  compu method CompuMethod_MCUM_TMS_MotSelfHeatEnSts: raw=phys for phys 0..1
  compu method CompuMethod_VCU_Ped_AccPedLSigVolt: raw=phys*20 for phys 0..6
  compu method CompuMethod_MCUM_CtrlModeVD: raw=phys for phys 0..1
  compu method CompuMethod_VCU_EngineIdleReq: raw=phys for phys 0..1
  compu method CompuMethod_MCUM_UDS_HW2: raw=phys for phys 0..255
  compu method CompuMethod_PosDly_Enable: raw=phys for phys 0..1
  compu method CompuMethod_MCUM_NMControlRMR: raw=phys for phys 0..1
  compu method CompuMethod_MCUM_MaxTorqueAllow: raw=phys*10+5000 for phys -500..500
  compu method CompuMethod_MCUM_UDS_Supplier6: raw=phys for phys 0..255
  compu method CompuMethod_EOL_FDrvRequesSpeed: raw=phys+17000 for phys -17000..17000
  compu method CompuMethod_MCUM_Derate_Reason: raw=phys for phys 0..15
  compu method CompuMethod_EOL_ThrottlePosition: raw=phys*2.544529262 for phys 0..100
  compu method CompuMethod_MCUM_NVMFail_Cnt: raw=phys for phys 0..15
  compu method CompuMethod_MCUS_WarningLevel: raw=phys for phys 0..3
  compu method CompuMethod_VCU_REsystemFaultSts: raw=phys for phys 0..1
  compu method CompuMethod_VCU_DIn_BrkPedOpen: raw=phys for phys 0..1
  compu method CompuMethod_VCU_Alw_Cabin220VInverter_Sts: raw=phys for phys 0..1
  compu method CompuMethod_VCU_LowPwr_AcChgPwrVolt: raw=phys*5 for phys 0..51
  compu method CompuMethod_VCU_EngineStartFailure_ID514: raw=phys for phys 0..1
  compu method CompuMethod_CDU_SelfCheckSt: raw=phys for phys 0..1
  compu method CompuMethod_ECM_Total_fuel_consumed: raw=phys*100 for phys 0..16777216
  compu method CompuMethod_MCUM_PWM_Err_Count: raw=phys for phys 0..31
  compu method CompuMethod_Debug_MCU_DrvMotorWorkSts: raw=phys for phys 0..3
  compu method CompuMethod_MCUM_HeatPwrMax: raw=phys*0.01 for phys 0..12800
  compu method CompuMethod_ECM_CatalystWarmUpReq: raw=phys for phys 0..1
  compu method CompuMethod_VCU_BrakePedalSts_P: raw=phys for phys 0..1
  compu method CompuMethod_U8_CMD3: raw=phys for phys 0..255
  compu method CompuMethod_MCUM_FaultData56: raw=phys for phys 0..255
  compu method CompuMethod_GCU_MainWireCurr: raw=phys*10+10000 for phys -1000..1000
  compu method CompuMethod_BMS_ChargeRequest: raw=phys for phys 0..1
  compu method CompuMethod_DCDC_CRC_324: raw=phys for phys 0..255
  compu method CompuMethod_IMParaIdent_IdentSubStep: raw=phys for phys 0..30
  compu method CompuMethod_MCUM_HWDrvUV_RstCnt: raw=phys for phys 0..15
  compu method CompuMethod_IMParaIdent_TotalLo: raw=phys*1000000 for phys 0..0.01
  compu method CompuMethod_GCU_SystemWarning: raw=phys for phys 0..1
  compu method CompuMethod_VCU_EngineFuelInhibitReq: raw=phys for phys 0..1
  compu method CompuMethod_VCU_APS2Position: raw=phys*2.544529262 for phys 0..100
  compu method CompuMethod_MCUM_FaultData14: raw=phys for phys 0..1.8446744073709552e+19
  compu method CompuMethod_MCUM_NMControl_PNC25: raw=phys for phys 0..1
  compu method CompuMethod_VCU_LowPwr_DcChgPwrVolt: raw=phys*5 for phys 0..51
  compu method CompuMethod_ECM_ActualEngineTorqueValid: raw=phys for phys 0..1
  compu method CompuMethod_VCU_EngineStartReq: raw=phys for phys 0..1
  compu method CompuMethod_VCU_EnergyMode: raw=phys for phys 0..7
  compu method CompuMethod_ECM_FuelConsumption: raw=phys*0.25 for phys 0..1020
  compu method CompuMethod_VCU_EolCfg_AEB: raw=phys for phys 0..1
  compu method CompuMethod_MotClb_FaultCode2: raw=phys for phys 0..255
  compu method CompuMethod_MCUM_FaultData61: raw=phys for phys 0..255
  compu method CompuMethod_EOL_ModeCMD_Check: raw=phys for phys 0..255
  compu method CompuMethod_ICU_REMode: raw=phys for phys 0..7
  compu method CompuMethod_DCDC_Over_Input_Voltage: raw=phys for phys 0..1
  compu method CompuMethod_MCUM_CurrTheta_Comp: raw=phys*10+250 for phys -25..25
  compu method CompuMethod_GainIden_Rslt_V: raw=phys*1000-700 for phys 0.7..1.2
  compu method CompuMethod_DCDC_Real_Input_Current: raw=phys*10 for phys 0..10
  compu method CompuMethod_EddyCur_IdenFinish_Flag: raw=phys for phys 0..1
  compu method CompuMethod_VCU_SpdLimitReason: raw=phys for phys 0..7
  compu method CompuMethod_MCUM_FaultData12: raw=phys for phys 0..255
  compu method CompuMethod_MCUS_SelfCheckSts: raw=phys for phys 0..3
  compu method CompuMethod_MotClb_IGBT_Temp1: raw=phys+50 for phys -50..205
  compu method CompuMethod_MCUM_ASC_Stop_Flag: raw=phys for phys 0..1
  compu method CompuMethod_GW_TBOXSOC_Altitude: raw=phys+1000 for phys -1000..10000
  compu method CompuMethod_MCUM_HighVoltPowerOffReq: raw=phys for phys 0..1
  compu method CompuMethod_OBC_HardwareSts: raw=phys for phys 0..1
  compu method CompuMethod_GW_RollingCounter_3B1: raw=phys for phys 0..15
  compu method CompuMethod_OBC_CPDutyCycleValue: raw=phys for phys 0..100
  compu method CompuMethod_VCU_FaultData9: raw=phys for phys 0..255
  compu method CompuMethod_MCUM_ResetReason: raw=phys for phys 0..255
  compu method CompuMethod_GW_IBC_RRWheelDirection: raw=phys for phys 0..3
  compu method CompuMethod_VCU_SMotSelfHeatLvlReq: raw=phys for phys 0..7
  compu method CompuMethod_MCUM_NVM_RslvrDirRFault: raw=phys for phys 0..1
  compu method CompuMethod_VCU_BCM_Authentication_MAC_A7: raw=phys for phys 0..255
  compu method CompuMethod_VCU_VehiMode_VehiHvCmd: raw=phys for phys 0..1
  compu method CompuMethod_MCUM_Us_Out: raw=phys*10 for phys 0..200
  compu method CompuMethod_BCM_Cabin220VHVIL_STs: raw=phys for phys 0..1
  compu method CompuMethod_VCU_DriverAssistProhibitSts: raw=phys for phys 0..1
  compu method CompuMethod_MCUM_PCBTemp: raw=phys+50 for phys -50..200
  compu method CompuMethod_U8_CMD1: raw=phys for phys 0..255
  compu method CompuMethod_DCDC_Derating: raw=phys for phys 0..1
  compu method CompuMethod_VCU_EnergyCtrlMode: raw=phys for phys 0..1
  compu method CompuMethod_CCM_APTC_Power: raw=phys*0.02 for phys 0..10000
  compu method CompuMethod_BCM_ON2BRelaySts: raw=phys for phys 0..1
  compu method CompuMethod_MCUM_UDS_HW8: raw=phys for phys 0..255
  compu method CompuMethod_VCU_DIn_AcChgPwr: raw=phys for phys 0..1
  compu method CompuMethod_MCUM_Offset_IU: raw=phys for phys 0..5000
  compu method CompuMethod_Harness_HWRdc: raw=phys for phys 0..1
  compu method CompuMethod_CurrLoad_CurExt_W: raw=phys+2000 for phys -2000..2095
  compu method CompuMethod_EOL_RollingCounter_13B: raw=phys for phys 0..15
  compu method CompuMethod_VCU_SDrvControlMode: raw=phys for phys 0..1
  compu method CompuMethod_VCU_Chg_DcChgerConSts: raw=phys for phys 0..1
  compu method CompuMethod_MotClb_Volt_DC: raw=phys*10 for phys 0..6553.5
  compu method CompuMethod_VCU_ShowCarModeSts: raw=phys for phys 0..1
  compu method CompuMethod_MCUM_UserDefine_Byte4: raw=phys for phys 0..255
  compu method CompuMethod_VCU_FaultData3: raw=phys for phys 0..255
  compu method CompuMethod_GTC_TestSts: raw=phys for phys 0..2
  compu method CompuMethod_MCUM_ActiveReleaseSts: raw=phys for phys 0..3
  compu method CompuMethod_OBC_StartSts: raw=phys for phys 0..1
  compu method CompuMethod_VCU_Vehicle_PreReqChgPwr: raw=phys for phys 0..250
  compu method CompuMethod_MCUM_FaultData16: raw=phys for phys 0..255
  compu method CompuMethod_BCM_DCChrgPwr_Volt_ID291: raw=phys*5 for phys 0..51
  compu method CompuMethod_GW_IBC_PlungerPressure_Q: raw=phys for phys 0..1
  compu method CompuMethod_BMS_RemainEnergy: raw=phys*0.1 for phys 0..655300
  compu method CompuMethod_VCU_DCChgHVILSts: raw=phys for phys 0..1
  compu method CompuMethod_GCU_MainWireVolt: raw=phys*10 for phys 0..500
  compu method CompuMethod_MCUM_FaultData37: raw=phys for phys 0..255
  compu method CompuMethod_ECM_FuelCloseLoopSts: raw=phys for phys 0..1
  compu method CompuMethod_GW_IBC_EPB_Status: raw=phys for phys 0..7
  compu method CompuMethod_OBC_CPDutyCycleFault: raw=phys for phys 0..1
  compu method CompuMethod_ECM_EngineStartedCompleted: raw=phys for phys 0..1
  compu method CompuMethod_BMS_BatDyn_Dchgpwr: raw=phys*10 for phys 0..500
  compu method CompuMethod_GW_IBC_FRWheelSpeedKPH: raw=phys*100 for phys 0..450
  compu method CompuMethod_ECM_TankPressure: raw=phys*10+200 for phys -20..40
  compu method CompuMethod_R16_CMD4: raw=phys*10000+32768 for phys -3.2768..3.2767
  compu method CompuMethod_EOL_MotClb_Enable: raw=phys for phys 0..3
  compu method CompuMethod_VCU_REsystemSts: raw=phys for phys 0..1
  compu method CompuMethod_IVI_CampingModeSW: raw=phys for phys 0..1
  compu method CompuMethod_MCUM_UDS_SW7: raw=phys for phys 0..255
  compu method CompuMethod_DCDC_Over_Input_Current: raw=phys for phys 0..1
  compu method CompuMethod_Harness_HWVoltLower: raw=phys for phys 0..1
  compu method CompuMethod_MCUM_NVM_RslvrDelayRFault: raw=phys for phys 0..1
  compu method CompuMethod_MotClb_IdSet: raw=phys*10+10000 for phys -1000..1000
  compu method CompuMethod_MCUS_HVILSts: raw=phys for phys 0..1
  compu method CompuMethod_EddyCur_ReadSuccess_Flag: raw=phys for phys 0..1
  compu method CompuMethod_MCUM_ActualTorqueFB: raw=phys*10+5000 for phys -500..500
  compu method CompuMethod_ECM_UDS_PhyReq_Byte4: raw=phys for phys 0..1
  compu method CompuMethod_VCU_MCUSDampgLmtFactor: raw=phys for phys 0..100
  compu method CompuMethod_EOL_SuppressJitterRMCURequest: raw=phys for phys 0..1
  compu method CompuMethod_Harness_HVIL_State: raw=phys for phys 0..1
  compu method CompuMethod_ECM_SWVersionA: raw=phys for phys 0..15
  compu method CompuMethod_Debug_MCU_DragSts: raw=phys for phys 0..3
  compu method CompuMethod_VCU_ElecPwrBalanceReq: raw=phys for phys 0..1
  compu method CompuMethod_MCUM_Torque_PwrEst: raw=phys+500 for phys -500..500
  compu method CompuMethod_Debug_MCU_HWRdcFault: raw=phys for phys 0..1
  compu method CompuMethod_BCM_RRDoorSts: raw=phys for phys 0..1
  compu method CompuMethod_GainIden_Rslt_W: raw=phys*1000-700 for phys 0.7..1.2
  compu method CompuMethod_EVCC_CPDutyCycleValue: raw=phys for phys 0..100
  compu method CompuMethod_MCUM_UserDefine_Word3: raw=phys for phys 0..65535
  compu method CompuMethod_ECM_UDS_PhyReq_Byte1: raw=phys for phys 0..1
  compu method CompuMethod_MCUM_FaultData11: raw=phys for phys 0..255
  compu method CompuMethod_BMS_BattIntakeTemp: raw=phys+40 for phys -40..210
  compu method CompuMethod_VCU_MotStartStopPowerUP: raw=phys*2 for phys 0..125
  compu method CompuMethod_MCUM_MotRotaryHeat_LvlFb: raw=phys for phys 0..7
  compu method CompuMethod_VCU_BCM_Authentication_MAC_A10: raw=phys for phys 0..255
  compu method CompuMethod_Debug_MCU_HVILSts: raw=phys for phys 0..1
  compu method CompuMethod_TMS_OutsideTemp_Corrected: raw=phys*2+80 for phys -40..87
  compu method CompuMethod_Harness_HWFoB: raw=phys for phys 0..1
  compu method CompuMethod_VCU_ACChgHVILSts: raw=phys for phys 0..1
  compu method CompuMethod_VCU_GearQuitAps: raw=phys for phys 0..1
  compu method CompuMethod_IVI_ForceChgTargetSOCVD: raw=phys for phys 0..1
  compu method CompuMethod_MCUM_FaultData54: raw=phys for phys 0..255
  compu method CompuMethod_VCU_MCUSMaxDischargePower: raw=phys for phys 0..510
  compu method CompuMethod_MCUS_MainWireVolt: raw=phys*10 for phys 0..1000
  compu method CompuMethod_EOL_FVehicleSts: raw=phys for phys 0..1
  compu method CompuMethod_MCUM_UDS_Boot9: raw=phys for phys 0..255
  compu method CompuMethod_BCM_PTCChksumErr: raw=phys for phys 0..1
  compu method CompuMethod_VCU_BCM_Authentication_MAC_A13: raw=phys for phys 0..255
  compu method CompuMethod_DCDC_Under_Output_Voltage: raw=phys for phys 0..1
  compu method CompuMethod_VCU_EngineRunAllowFlg_ID514: raw=phys for phys 0..1
  compu method CompuMethod_VCU_FaultData4: raw=phys for phys 0..255
  compu method CompuMethod_VCU_PwnIn_CcmHvilDutyFb: raw=phys for phys 0..100
  compu method CompuMethod_PosDly_Cal_RslvDelayTime: raw=phys*10000+30000 for phys -3..3
  compu method CompuMethod_MotClb_FaultCode7: raw=phys for phys 0..255
  compu method CompuMethod_TMS_MainMotPumpSpdResp: raw=phys*2.5 for phys 0..100
  compu method CompuMethod_MCUM_FaultData57: raw=phys for phys 0..255
  compu method CompuMethod_VCU_MCUMMaxNegDampgTrq: raw=phys+50 for phys -50..0
  compu method CompuMethod_MCUM_MotSelfHeat_DropLvlFb: raw=phys for phys 0..1
  compu method CompuMethod_MCUM_CtrlMode: raw=phys for phys 0..1
  compu method CompuMethod_ECM_UDS_Res_Byte1: raw=phys for phys 0..1
  compu method CompuMethod_CurrLoad_CurExt_V: raw=phys+2000 for phys -2000..2095
  compu method CompuMethod_ECM_EngineDFCOConditionRequest: raw=phys for phys 0..1
  compu method CompuMethod_VCU_Cabin220VRelay_Req: raw=phys for phys 0..1
  compu method CompuMethod_OfsIden_Finish: raw=phys for phys 0..1
  compu method CompuMethod_MCUM_Iq_LookUp: raw=phys+1000 for phys -1000..1000
  compu method CompuMethod_MCUM_EOL_StateMachine: raw=phys for phys 0..255
  compu method CompuMethod_MCUM_EOP_DCVolt: raw=phys*10 for phys 0..30
  compu method CompuMethod_MCUM_UserDefine_Byte2: raw=phys for phys 0..255
  compu method CompuMethod_MCUM_UDS_HW3: raw=phys for phys 0..255
  compu method CompuMethod_ICU_RollingCounter_24C: raw=phys for phys 0..15
  compu method CompuMethod_CCM_Volt: raw=phys for phys 0..1000
  compu method CompuMethod_MotClb_Motor_Temp1_Flt: raw=phys+50 for phys -50..205
  compu method CompuMethod_U8_CMD5: raw=phys for phys 0..255
  compu method CompuMethod_BCM_Cab220VHVIL_STs: raw=phys for phys 0..1
  compu method CompuMethod_BMS_CDUHVILSts: raw=phys for phys 0..1
  compu method CompuMethod_EMS_CRC_BE: raw=phys for phys 0..255
  compu method CompuMethod_EOL_VehicleSts: raw=phys for phys 0..1
  compu method CompuMethod_VCU_WLTCModeFlag: raw=phys for phys 0..1
  compu method CompuMethod_BMS_BatDyn_Chgpwr: raw=phys*10 for phys 0..500
  compu method CompuMethod_MCUM_Offset_IV: raw=phys for phys 0..5000
  compu method CompuMethod_MCUM_FaultData33: raw=phys for phys 0..255
  compu method CompuMethod_EOL_VehicleDirect: raw=phys for phys 0..1
  compu method CompuMethod_VCU_MMotSelfHeatEnReq: raw=phys for phys 0..1
  compu method CompuMethod_BCM_VCU_Authentication_Challenge_A1: raw=phys for phys 0..255
  compu method CompuMethod_VCU_GearLeverValid: raw=phys for phys 0..1
  compu method CompuMethod_U16_CMD3: raw=phys for phys 0..65535
  compu method CompuMethod_BMS_BattMinTemp: raw=phys+40 for phys -40..210
  compu method CompuMethod_OfsIden_SpdUp_Overtime: raw=phys for phys 0..1
  compu method CompuMethod_VCU_TrqDstrbutnPrio: raw=phys for phys 0..7
  compu method CompuMethod_IVI_SpeedLimitModeSW: raw=phys for phys 0..1
  compu method CompuMethod_BMS_Warning_Level: raw=phys for phys 0..3
  compu method CompuMethod_VCU_RollingCounter_BB: raw=phys for phys 0..15
  compu method CompuMethod_VCU_EngPreStartFlg: raw=phys for phys 0..1
  compu method CompuMethod_VCU_FuelChgModeMsg: raw=phys for phys 0..3
  compu method CompuMethod_VCU_FuelChgModeSts: raw=phys for phys 0..3
  compu method CompuMethod_VCU_RoughRoadDetectionFlag: raw=phys for phys 0..1
  compu method CompuMethod_VCU_Clutch_2_RequesSpeedValid: raw=phys for phys 0..1
  compu method CompuMethod_VCU_Clutch_1_RequesSpeedValid: raw=phys for phys 0..1
  compu method CompuMethod_PosDly_IdentFinish_Flag: raw=phys for phys 0..1
  compu method CompuMethod_MotClb_FaultCode6: raw=phys for phys 0..255
  compu method CompuMethod_ECM_UDS_Res_Byte6: raw=phys for phys 0..1
  compu method CompuMethod_VCU_FuelTankLockReq: raw=phys for phys 0..3
  compu method CompuMethod_GCU__PowerReduceSts: raw=phys for phys 0..1
  compu method CompuMethod_MCUM_FaultData58: raw=phys for phys 0..255
  compu method CompuMethod_VCU_EngineResetSts: raw=phys for phys 0..1
  compu method CompuMethod_VCU_MilLamp: raw=phys for phys 0..1
  compu method CompuMethod_MotClb_UdFb: raw=phys*10+10000 for phys -1000..1000
  compu method CompuMethod_BCM_VehlockCtrl: raw=phys for phys 0..3
  compu method CompuMethod_EVCC_EVSEMaximumPowerLimit: raw=phys*0.1 for phys 0..650000
  compu method CompuMethod_VCU_MDrvRequestTorque: raw=phys*10+5000 for phys -500..500
  compu method CompuMethod_PosDly_FauPro_Chk_RslvOfst_OVal: raw=phys for phys 0..1
  compu method CompuMethod_VCU_DynamicChgPwr: raw=phys+10 for phys -10..10
  compu method CompuMethod_MCUM_DrvMotorWorkSts: raw=phys for phys 0..3
  compu method CompuMethod_GW_RZCU_Cabin_220Vconnect_Sts: raw=phys for phys 0..1
  compu method CompuMethod_VCU_BMSEmergencyCmd: raw=phys for phys 0..1
  compu method CompuMethod_BMS_GCUHVILSts: raw=phys for phys 0..1
  compu method CompuMethod_MCUM_FaultData36: raw=phys for phys 0..255
  compu method CompuMethod_GainIden_Curr_Peak_V: raw=phys*10+1000 for phys -100..100
  compu method CompuMethod_VCU_MotChargePower: raw=phys*2 for phys 0..127
  compu method CompuMethod_BMS_WkupVolt_AC12V: raw=phys*5 for phys 0..50
  compu method CompuMethod_VCU_AdditionalPwrVal: raw=phys for phys 0..250
  compu method CompuMethod_U8_CMD4: raw=phys for phys 0..255
  compu method CompuMethod_MCUM_FaultData51: raw=phys for phys 0..255
  compu method CompuMethod_VCU_EolCfg_SpdLmtVal: raw=phys for phys 0..15
  compu method CompuMethod_MCUM_CpldRest_TimeOut_flag: raw=phys for phys 0..3
  compu method CompuMethod_VCU_TrqDstrbutnTransferSts: raw=phys for phys 0..7
  compu method CompuMethod_DCDC_Hardware_Fault_Flag: raw=phys for phys 0..1
  compu method CompuMethod_VCU_AuthenticationKey_WSts: raw=phys for phys 0..1
  compu method CompuMethod_MCUM_Torque_Ref: raw=phys+500 for phys -500..500
  compu method CompuMethod_VCU_VehiPowrConsumption: raw=phys*100+2000 for phys -20..50
  compu method CompuMethod_VCU_SinglePedalSts: raw=phys for phys 0..1
  compu method CompuMethod_MCUM_UDS_Boot5: raw=phys for phys 0..255
  compu method CompuMethod_VCU_REStopReq: raw=phys for phys 0..1
  compu method CompuMethod_VCU_Spd_VehiAccnFilt: raw=phys*20+100 for phys -5..7.75
  compu method CompuMethod_VCU_FaultData5: raw=phys for phys 0..255
  compu method CompuMethod_MCUM_UDS_Boot2: raw=phys for phys 0..255
  compu method CompuMethod_MCUM_IGBTTemp_V: raw=phys+50 for phys -50..200
  compu method CompuMethod_MCUM_InletTemp: raw=phys+50 for phys -50..200
  compu method CompuMethod_EddyCur_Para_Sin_m: raw=phys+2048 for phys -2000..2000
  compu method CompuMethod_BMS_SOCModifyFlag: raw=phys for phys 0..1
  compu method CompuMethod_OBC_DCVolt: raw=phys*10 for phys 0..1000
  compu method CompuMethod_VCU_LowPwr_LowBatt2Volt: raw=phys*4 for phys 0..31.75
  compu method CompuMethod_OfsIden_ZeroAlign_OverTime: raw=phys for phys 0..1
  compu method CompuMethod_MCUM_DrvPwrEn_Out_State: raw=phys for phys 0..1
  compu method CompuMethod_MCUM_MotSelfHeat_EnSts: raw=phys for phys 0..3
  compu method CompuMethod_BMS_VoltHiDeratLevel_NA: raw=phys for phys 0..3
  compu method CompuMethod_PosDly_FauPro_Chk_DlyTime_OVal: raw=phys for phys 0..1
  compu method CompuMethod_MotClb_Spd_rpm_Flt: raw=phys+17000 for phys -17000..30000
  compu method CompuMethod_VCU_MDrvRequesSpeedVD: raw=phys for phys 0..1
  compu method CompuMethod_VCU_STorqueReq: raw=phys*2+1000 for phys -500..1547
  compu method CompuMethod_VCU_RMCUMaxMechDischrgPower: raw=phys for phys 0..510
  compu method CompuMethod_MCUM_FaultData42: raw=phys for phys 0..255
  compu method CompuMethod_VCU_Vehicle_Warning: raw=phys for phys 0..3
  compu method CompuMethod_GCU_ControlMode: raw=phys for phys 0..7
  compu method CompuMethod_EOL_MCUMDampgLmtFactor: raw=phys for phys 0..100
  compu method CompuMethod_MotClb_FaultCode3: raw=phys for phys 0..255
  compu method CompuMethod_MCUM_FaultData21: raw=phys for phys 0..255
  compu method CompuMethod_BMS_RNegativeRelayFB: raw=phys for phys 0..1
  compu method CompuMethod_MCUM_FaultData43: raw=phys for phys 0..255
  compu method CompuMethod_GCU_SWVersionC: raw=phys for phys 0..254
  compu method CompuMethod_FstRcrd_Enable: raw=phys for phys 0..1
  compu method CompuMethod_ECM_EngineIdleStateRequest: raw=phys for phys 0..1
  compu method CompuMethod_VCU_FaultData12: raw=phys for phys 0..255
  compu method CompuMethod_MCUM_FaultData31: raw=phys for phys 0..255
  compu method CompuMethod_VCU_MotStartStopPowerLOW: raw=phys*2 for phys 0..125
  compu method CompuMethod_MCUM_UDS_Supplier3: raw=phys for phys 0..255
  compu method CompuMethod_MCUM_PosTransduserFaultCode: raw=phys for phys 0..255
  compu method CompuMethod_MCUM_UDS_HW1: raw=phys for phys 0..255
  compu method CompuMethod_GW_IBC_FLWheelDirection: raw=phys for phys 0..3
  compu method CompuMethod_VCU_AlwDCChargeSts: raw=phys for phys 0..1
  compu method CompuMethod_VCU_MCUSActiveReleaseCmd: raw=phys for phys 0..1
  compu method CompuMethod_MCUM_RawSinCorr: raw=phys+2000 for phys -2000..2000
  compu method CompuMethod_VCU_PWakeupSt: raw=phys for phys 0..1
  compu method CompuMethod_ECM_TankPressureValid: raw=phys for phys 0..1
  compu method CompuMethod_MCUM_UDS_Supplier5: raw=phys for phys 0..255
  compu method CompuMethod_MCUM_SeriousWarning_Level: raw=phys for phys 0..3
  compu method CompuMethod_BMS_IsoRessistanceSts: raw=phys for phys 0..1
  compu method CompuMethod_CurrLoad_offset_Iv: raw=phys for phys 0..4095
  compu method CompuMethod_VCU_Cab220VRelay_Req: raw=phys for phys 0..1
  compu method CompuMethod_Harness_igbt_temp3: raw=phys+50 for phys -50..205
  compu method CompuMethod_MCUM_FaultData28: raw=phys for phys 0..255
  compu method CompuMethod_U8_CMD6: raw=phys for phys 0..255
  compu method CompuMethod_GCU_HVILSts: raw=phys for phys 0..1
  compu method CompuMethod_MotClb_CoolWater_Temp: raw=phys+50 for phys -50..65485
  compu method CompuMethod_MCUM_WakeUpReason: raw=phys for phys 0..127
  compu method CompuMethod_VCU_ACOffReq: raw=phys for phys 0..3
  compu method CompuMethod_IVI_ForceChgModeReq: raw=phys for phys 0..1
  compu method CompuMethod_MCUM_EOP_FaultCode: raw=phys for phys 0..7
  compu method CompuMethod_IVI_Data: raw=phys for phys 0..31
  compu method CompuMethod_BMS_MILlampReq: raw=phys for phys 0..1
  compu method CompuMethod_MotClb_OfsApply: raw=phys*100 for phys 0..360
  compu method CompuMethod_MCUM_UserDefine_20ms: raw=phys for phys 0..127
  compu method CompuMethod_VCU_BCM_Authentication_MAC_A2: raw=phys for phys 0..255
  compu method CompuMethod_IBS_CRC_225: raw=phys for phys 0..255
  compu method CompuMethod_MCUM_FaultData52: raw=phys for phys 0..255
  compu method CompuMethod_MCUM_DrvMotorRPMVD: raw=phys for phys 0..1
  compu method CompuMethod_VCU_EngineOff_Flag: raw=phys for phys 0..1
  compu method CompuMethod_EOL_frqsync: raw=phys for phys 0..65535
  compu method CompuMethod_GW_TCM_Counter_RND: raw=phys for phys 0..15
  compu method CompuMethod_MCUM_UDS_SW10: raw=phys for phys 0..255
  compu method CompuMethod_MCUM_UDS_Supplier2: raw=phys for phys 0..255
  compu method CompuMethod_BMS_Integrity_Check: raw=phys for phys 0..1
  compu method CompuMethod_VCU_BCM_Authentication_Challenge_B0: raw=phys for phys 0..255
  compu method CompuMethod_MCUM_MotorTempAlarm: raw=phys for phys 0..1
  compu method CompuMethod_GCU_Warning_Level: raw=phys for phys 0..3
  compu method CompuMethod_EOL_RMCUMaxDischargePower: raw=phys for phys 0..510
  compu method CompuMethod_MCUM_MotBlockHeat_LvlFb: raw=phys for phys 0..7
  compu method CompuMethod_GainIden_CurrRMS_Ref_U: raw=phys*10 for phys 0..800
  compu method CompuMethod_EOL_Asc_CMD: raw=phys for phys 0..3
  compu method CompuMethod_BCM_FLDoorSts: raw=phys for phys 0..1
  compu method CompuMethod_VCU_GearLevelPosSts: raw=phys for phys 0..3
  compu method CompuMethod_MCUM_IGBTTemp_W: raw=phys+50 for phys -50..200
  compu method CompuMethod_VCU_MotSelfHeatLvlFb: raw=phys for phys 0..15
  compu method CompuMethod_VCU_MCUMWaterPumpLevlReq: raw=phys for phys 0..15
  compu method CompuMethod_VCU_MCUSWaterPumpLevlReq: raw=phys for phys 0..15
  compu method CompuMethod_VCU_MCUMDiffProtectSts: raw=phys for phys 0..1
  compu method CompuMethod_GainIden_Curr_Peak_U: raw=phys*10+1000 for phys -100..100
  compu method CompuMethod_VCU_EolCfg_MotPwr: raw=phys for phys 0..7
  compu method CompuMethod_Harness_I_W: raw=phys*20.48001049 for phys 0..12.4512
  compu method CompuMethod_MCUM_HWFoT_RstCnt: raw=phys for phys 0..15
  compu method CompuMethod_BCM_VehLockSts: raw=phys for phys 0..1
  compu method CompuMethod_CurrLoad_offset_Iw: raw=phys for phys 0..4095
  compu method CompuMethod_MCUM_FaultData15: raw=phys for phys 0..255
  compu method CompuMethod_VCU_MCUMDampgLmtFactor: raw=phys for phys 0..100
  compu method CompuMethod_ICU_TotalOdometerkm: raw=phys for phys 0..999999
  compu method CompuMethod_MCUS_RollingCounter_DB: raw=phys for phys 0..15
  compu method CompuMethod_MCUM_NVM_HallGainRFault: raw=phys for phys 0..1
  compu method CompuMethod_ECM_EngineCoolantTempValid: raw=phys for phys 0..1
  compu method CompuMethod_VCU_SinglePedalSts_ID514: raw=phys for phys 0..1
  compu method CompuMethod_ECM_MilLampRequest: raw=phys for phys 0..3
  compu method CompuMethod_EOL_GearLevelPosSts: raw=phys for phys 0..3
  compu method CompuMethod_VCU_HighVoltFailed_M: raw=phys for phys 0..1
  compu method CompuMethod_VCU_REVehiWheelTrqReq: raw=phys for phys 0..255
  compu method CompuMethod_ECM_UDS_PhyReq_Byte2: raw=phys for phys 0..1
  compu method CompuMethod_MCUM_SBC_SelfCheckFault: raw=phys for phys 0..1
  compu method CompuMethod_ECM_SWVersionB: raw=phys for phys 0..254
  compu method CompuMethod_VCU_VehPreHVPwrOffCmd: raw=phys for phys 0..1
  compu method CompuMethod_GCU_Temp: raw=phys+40 for phys -40..210
  compu method CompuMethod_EOL_ActiveReleaseCmd: raw=phys for phys 0..1
  compu method CompuMethod_VCU_MDrvControlMode: raw=phys for phys 0..1
  compu method CompuMethod_VCU_Ped_AccPedHSigVolt: raw=phys*20 for phys 0..6
  compu method CompuMethod_MCUM_HeatPwrAllwd: raw=phys for phys 0..1
  compu method CompuMethod_ECM_SelfCheckSt: raw=phys for phys 0..1
  compu method CompuMethod_ECM_PCVPipeDiagReq: raw=phys for phys 0..1
  compu method CompuMethod_Harness_PWM_DIR: raw=phys for phys 0..255
  compu method CompuMethod_MCUM_MotBlockHeat_CurMag: raw=phys for phys 0..500
  compu method CompuMethod_DCDC_WorkSts: raw=phys for phys 0..3
  compu method CompuMethod_VCU_On2KL15_Volt: raw=phys*0.01 for phys 0..20000
  compu method CompuMethod_VCU_ClutchWrkModDebug: raw=phys for phys 0..31
  compu method CompuMethod_MCUM_UDS_Boot10: raw=phys for phys 0..255
  compu method CompuMethod_ECM_ActualEngineTorque: raw=phys*2+1000 for phys -500..1547
  compu method CompuMethod_CurrLoad_CurExt_U: raw=phys+2000 for phys -2000..2095
  compu method CompuMethod_VCU_UnlockBeforeDriving: raw=phys for phys 0..1
  compu method CompuMethod_PosDly_Write_Flag: raw=phys for phys 0..1
  compu method CompuMethod_GainIden_Is_Samp_V: raw=phys*10 for phys 0..1000
  compu method CompuMethod_VCU_BCM_Authentication_MAC_A6: raw=phys for phys 0..255
  compu method CompuMethod_MotClb_ErrLevel: raw=phys for phys 0..3
  compu method CompuMethod_VCU_EolCfg_FPTCIL: raw=phys for phys 0..1
  compu method CompuMethod_MCUM_Id_LookUp: raw=phys+1000 for phys -1000..1000
  compu method CompuMethod_GW_ACU_FRSeatBeltRSt: raw=phys for phys 0..3
  compu method CompuMethod_Debug_MCU_HighVoltPowerOffReq: raw=phys for phys 0..1
  compu method CompuMethod_ECM_EngineTorqueLoss: raw=phys*2+200 for phys -100..411
  compu method CompuMethod_VCU_PreventSliding: raw=phys for phys 0..1
  compu method CompuMethod_MotClb_FaultCode4: raw=phys for phys 0..255
  compu method CompuMethod_DCDC_Over_Output_Voltage: raw=phys for phys 0..1
  compu method CompuMethod_GW_ACU_TotalCrashOutputSts: raw=phys for phys 0..1
  compu method CompuMethod_IVI_FuelDetMode: raw=phys for phys 0..1
  compu method CompuMethod_GainIden_Curr_Peak_W: raw=phys*10+1000 for phys -100..100
  compu method CompuMethod_MCUM_SBC_FeedDogFault: raw=phys for phys 0..1
  compu method CompuMethod_MCUM_MainSt_State: raw=phys for phys 0..15
  compu method CompuMethod_OBC_CRC_316: raw=phys for phys 0..255
  compu method CompuMethod_MCUM_NVM_RslvrParamRFault: raw=phys for phys 0..1
  compu method CompuMethod_VCU_Chg_AcChgerConSts: raw=phys for phys 0..1
  compu method CompuMethod_BCM_VCU_Authentication_MAC_B7: raw=phys for phys 0..255
  compu method CompuMethod_VCU_BCM_Authentication_Challenge_B3: raw=phys for phys 0..255
  compu method CompuMethod_Debug_MCU_CRC_CA: raw=phys for phys 0..255
  compu method CompuMethod_VCU_OpeartingMode: raw=phys for phys 0..3
  compu method CompuMethod_MCUM_NVM_MotorTypeRFault: raw=phys for phys 0..1
  compu method CompuMethod_EVCC_CP_status: raw=phys for phys 0..14
  compu method CompuMethod_MCUM_UDS_ProductModel4: raw=phys for phys 0..255
  compu method CompuMethod_GW_BZCU_FuelTankStsLockSts: raw=phys for phys 0..3
  compu method CompuMethod_PTC_BscSts: raw=phys for phys 0..1
  compu method CompuMethod_PTC_RollingCounter_367: raw=phys for phys 0..15
  compu method CompuMethod_PTC_Fault: raw=phys for phys 0..1
  compu method CompuMethod_EOL_RDrvRequestTorque: raw=phys*10+5000 for phys -500..500
  compu method CompuMethod_IVI_EMSRepairModeReq: raw=phys for phys 0..1
  compu method CompuMethod_BMS_ChargerDCInput: raw=phys for phys 0..1
  compu method CompuMethod_MotClb_UsOutFlt: raw=phys*10+10000 for phys -1000..5553.5
  compu method CompuMethod_IVI_SpeedLimitModeSpeed: raw=phys for phys 1..180
  compu method CompuMethod_MCUM_DrvMotorRPM: raw=phys+17000 for phys -17000..30000
  compu method CompuMethod_MCUS_Clutch_Fault: raw=phys for phys 0..15
  compu method CompuMethod_MCUS_TMS_FrMotSelfHeatEnSts: raw=phys for phys 0..1
  compu method CompuMethod_MCUS_TMS_FrMotSelfHeatLvlFb: raw=phys for phys 0..7
  compu method CompuMethod_VCU_GearLevelPosFault: raw=phys for phys 0..1
  compu method CompuMethod_VCU_ForceChgPwr: raw=phys+10 for phys -10..10
  compu method CompuMethod_MCUM_IGBTTemp: raw=phys+50 for phys -50..200
  compu method CompuMethod_GW_IBC_VehicleSpeed: raw=phys*100 for phys 0..450
  compu method CompuMethod_EddyCur_IdenFail_Flag: raw=phys for phys 0..1
  compu method CompuMethod_VCU_SlopeEst_Valid: raw=phys for phys 0..1
  compu method CompuMethod_BCM_VCU_Authentication_MAC_B15: raw=phys for phys 0..255
  compu method CompuMethod_IMParaIdent_Rr: raw=phys*10000 for phys 0..0.1
  compu method CompuMethod_GCU_CRC_BD: raw=phys for phys 0..255
  compu method CompuMethod_GCU_EngineCylinderDeactivationStatus: raw=phys for phys 0..3
  compu method CompuMethod_GCU_EngineFuelInhibitReq: raw=phys for phys 0..1
  compu method CompuMethod_VCU_GCUActiveReleaseCmd: raw=phys for phys 0..1
  compu method CompuMethod_Debug_MCUM_TMS_MotSelfHeatEnSts: raw=phys for phys 0..1
  compu method CompuMethod_VCU_DcChgPwrSts: raw=phys for phys 0..1
  compu method CompuMethod_VCU_Pwr_WheelMaxDrvTrq: raw=phys*0.1 for phys 0..10000
  compu method CompuMethod_EOL_FDrvRequestTorqueVD: raw=phys for phys 0..1
  compu method CompuMethod_ECM_UDS_Res_Byte5: raw=phys for phys 0..1
  compu method CompuMethod_MCUS_HWRdcFault: raw=phys for phys 0..1
  compu method CompuMethod_DelayIden_Write_Finish: raw=phys for phys 0..1
  compu method CompuMethod_BMS_MCUMHVILSts: raw=phys for phys 0..1
  compu method CompuMethod_MCUM_RollingCounter_CA: raw=phys for phys 0..15
  compu method CompuMethod_MCUM_Spd_Turn: raw=phys for phys 0..17000
  compu method CompuMethod_Debug_MCUM_HeatPwrAval: raw=phys for phys 0..31
  compu method CompuMethod_IMParaIdent_Rs: raw=phys*10000 for phys 0..0.1
  compu method CompuMethod_VCU_DIn_ColumnShiftP: raw=phys for phys 0..1
  compu method CompuMethod_EOL_FDrvRequesSpeedVD: raw=phys for phys 0..1
  compu method CompuMethod_BMS_BattCurr: raw=phys*10+15000 for phys -1500..1500
  compu method CompuMethod_VCU_Ped_AccPedLPwrVolt: raw=phys*10 for phys 0..12
  compu method CompuMethod_VCU_MilLampRequest_ID514: raw=phys for phys 0..1
  compu method CompuMethod_MCUM_FaultData41: raw=phys for phys 0..255
  compu method CompuMethod_BCM_VehicleRepairMode: raw=phys for phys 0..1
  compu method CompuMethod_MCUM_FaultData5: raw=phys for phys 0..255
  compu method CompuMethod_VCU_GCURequesSpeed: raw=phys+8000 for phys -8000..8000
  compu method CompuMethod_VCU_EolCfg_EPB: raw=phys for phys 0..1
  compu method CompuMethod_VCU_Crash_VehiCrashSts: raw=phys for phys 0..1
  compu method CompuMethod_U16_CMD1: raw=phys for phys 0..65535
  compu method CompuMethod_VCU_SDrvRequesSpeed: raw=phys+17000 for phys -17000..30000
  compu method CompuMethod_CurrLoad_offset_Iu: raw=phys for phys 0..4095
  compu method CompuMethod_OBC_DCSts: raw=phys for phys 0..1
  compu method CompuMethod_VCU_PowerModeAllow: raw=phys for phys 0..3
  compu method CompuMethod_BMS_CRC_1A1: raw=phys for phys 0..255
  compu method CompuMethod_HPCBCM_NM_PNC7: raw=phys for phys 0..1
  compu method CompuMethod_GTC_TestRslt: raw=phys for phys 0..1
  compu method CompuMethod_VCU_ParkBeforeGear: raw=phys for phys 0..1
  compu method CompuMethod_MCUM_MaxSpeedAllow: raw=phys+17000 for phys -17000..17000
  compu method CompuMethod_OfsIden_IdenDiverge: raw=phys for phys 0..1
  compu method CompuMethod_GCU_TransientPower: raw=phys*10 for phys 0..250
  compu method CompuMethod_VCU_VehicleNegTrqRspdSts: raw=phys for phys 0..1
  compu method CompuMethod_ECM_CatalystWarmUpSts: raw=phys for phys 0..1
  compu method CompuMethod_MCUM_UDS_SW6: raw=phys for phys 0..255
  compu method CompuMethod_Harness_HWFoT: raw=phys for phys 0..1
  compu method CompuMethod_MCUM_UDS_SW1: raw=phys for phys 0..255
  compu method CompuMethod_VCU_BCM_Authentication_MAC_A0: raw=phys for phys 0..255
  compu method CompuMethod_GW_TCM_ParkingSwSts: raw=phys for phys 0..3
  compu method CompuMethod_U16_CMD4: raw=phys for phys 0..65535
  compu method CompuMethod_PosDly_Stage: raw=phys for phys 0..6
  compu method CompuMethod_OfsIden_IFStart_Fail: raw=phys for phys 0..1
  compu method CompuMethod_TMS_MainMotPump_Operation_Temp: raw=phys+50 for phys -50..200
  compu method CompuMethod_VCU_SDrvRequestTorqueVD: raw=phys for phys 0..1
  compu method CompuMethod_VCU_SuppressJitterMCUSRequest: raw=phys for phys 0..1
  compu method CompuMethod_VCU_GearLevelPosFault_ID514: raw=phys for phys 0..1
  compu method CompuMethod_Harness_igbt_temp2: raw=phys+50 for phys -50..205
  compu method CompuMethod_MCUM_UDS_Boot4: raw=phys for phys 0..255
  compu method CompuMethod_MCUM_FaultData18: raw=phys for phys 0..255
  compu method CompuMethod_TMS_MilLampReq: raw=phys for phys 0..3
  compu method CompuMethod_EddyCur_Para_Sin_k: raw=phys*10000 for phys 0..3
  compu method CompuMethod_EOL_ModeCMD_Data2: raw=phys for phys 0..255
  compu method CompuMethod_VCU_DriveSHVILSts: raw=phys for phys 0..1
  compu method CompuMethod_EOL_ModeCMD_Data5: raw=phys for phys 0..255
  compu method CompuMethod_MCUM_UDS_Boot3: raw=phys for phys 0..255
  compu method CompuMethod_VCU_FaultData8: raw=phys for phys 0..255
  compu method CompuMethod_MCUM_CurrAmp_Comp: raw=phys+100 for phys -100..100
  compu method CompuMethod_ECM_UDS_Res_Byte0: raw=phys for phys 0..1
  compu method CompuMethod_VCU_GCUAassistFB: raw=phys for phys 0..1
  compu method CompuMethod_BCM_VCU_Authentication_MAC_B11: raw=phys for phys 0..255
  compu method CompuMethod_OBC_ACMaxPower: raw=phys*20+500 for phys -25..25
  compu method CompuMethod_Harness_V_DC: raw=phys*10 for phys 0..6553.5
  compu method CompuMethod_VCU_EngineAllowStop: raw=phys for phys 0..1
  compu method CompuMethod_BCM_CRC_291: raw=phys for phys 0..255
  compu method CompuMethod_BCM_ShutdownMode: raw=phys for phys 0..1
  compu method CompuMethod_BCM_NM_PNC_ON_1ADr_Sts: raw=phys for phys 0..1
  compu method CompuMethod_TMS_MCUMHeatModEnad: raw=phys for phys 0..1
  compu method CompuMethod_TMS_VCU_MotSelfHeatEnReq: raw=phys for phys 0..1
  compu method CompuMethod_TMS_VCU_MotSelfHeatLvlReq: raw=phys for phys 0..15
  compu method CompuMethod_VCU_HighPerforDisable: raw=phys for phys 0..1
  compu method CompuMethod_VCU_DCDCEnableCmd: raw=phys for phys 0..1
  compu method CompuMethod_VCU_AccFunc_CtlMode: raw=phys for phys 0..7
  compu method CompuMethod_MCUM_MotSelfHeat_DropLvlRsn: raw=phys for phys 0..3
  compu method CompuMethod_VCU_ACConnectSts: raw=phys for phys 0..1
  compu method CompuMethod_IVI_CarWashMode: raw=phys for phys 0..1
  compu method CompuMethod_DCDC_Under_Input_Voltage: raw=phys for phys 0..1
  compu method CompuMethod_MCUM_NMControlRMR_Sts: raw=phys for phys 0..1
  compu method CompuMethod_MCUM_Rotor_Position: raw=phys*10 for phys 0..360
  compu method CompuMethod_BMS_OBCWorkModeCtrl: raw=phys for phys 0..7
  compu method CompuMethod_EOL_ModeCMD_Data0: raw=phys for phys 0..255
  compu method CompuMethod_MCUM_FaultData30: raw=phys for phys 0..255
  compu method CompuMethod_MCUM_Offset_IW: raw=phys for phys 0..5000
  compu method CompuMethod_GCU_SWVersionB: raw=phys for phys 0..254
  compu method CompuMethod_VCU_FVVOpenReq: raw=phys for phys 0..1
  compu method CompuMethod_BCM_DriverDoorSts: raw=phys for phys 0..1
  compu method CompuMethod_MCUM_HVILSts: raw=phys for phys 0..1
  compu method CompuMethod_MCUM_FaultData8: raw=phys for phys 0..255
  compu method CompuMethod_OfsIden_Sts: raw=phys for phys 0..7
  compu method CompuMethod_OBC_ACCurr: raw=phys*10+1000 for phys -100..100
  compu method CompuMethod_MCUM_MainWireCurr: raw=phys*10+10000 for phys -1000..1000
  compu method CompuMethod_EOL_VehicleDirectVD: raw=phys for phys 0..1
  compu method CompuMethod_ICU_CLTCoilMileage: raw=phys for phys 0..2000
  compu method CompuMethod_MCUS_ActualTorqueFBVD: raw=phys for phys 0..1
  compu method CompuMethod_MCUS_MainWireCurr: raw=phys*10+10000 for phys -1000..1000
  compu method CompuMethod_ICU_CRC_24C: raw=phys for phys 0..255
  compu method CompuMethod_ICU_PHEVMode: raw=phys for phys 0..7
  compu method CompuMethod_MCUM_MILlampReq: raw=phys for phys 0..1
  compu method CompuMethod_BMS_SOC_target: raw=phys*10 for phys 0..100
  compu method CompuMethod_VCU_PDU220VRelay_Req: raw=phys for phys 0..1
  compu method CompuMethod_VCU_MCUSMaxChargePower: raw=phys for phys 0..510
  compu method CompuMethod_VCU_APS1Position: raw=phys*2.544529262 for phys 0..100
  compu method CompuMethod_ECM_FaultLevel: raw=phys for phys 0..3
  compu method CompuMethod_PosDly_RslvOffsetComp: raw=phys*10+30 for phys -3..3
  compu method CompuMethod_MCUM_ActualTorqueFBVD: raw=phys for phys 0..1
  compu method CompuMethod_VCU_SMotSelfHeatEnReq: raw=phys for phys 0..1
  compu method CompuMethod_BMS_SOC_Real: raw=phys*10 for phys 0..100
  compu method CompuMethod_ICU_CreepMode: raw=phys for phys 0..3
  compu method CompuMethod_MCUM_UserDefine_Word1: raw=phys for phys 0..65535
  compu method CompuMethod_MCUM_FaultData10: raw=phys for phys 0..255
  compu method CompuMethod_VCU_AccPedalValid: raw=phys for phys 0..1
  compu method CompuMethod_MCUM_Vq_Ref: raw=phys*0.5+500 for phys -1000..1000
  compu method CompuMethod_MCUM_UDS_SW5: raw=phys for phys 0..255
  compu method CompuMethod_VCU_REStartType: raw=phys for phys 0..31
  compu method CompuMethod_MCUM_500usOverTime_Cnt: raw=phys for phys 0..15
  compu method CompuMethod_ICU_TotalOilmeterkm: raw=phys for phys 0..999999
  compu method CompuMethod_VCU_BCM_Authentication_Challenge_B1: raw=phys for phys 0..255
  compu method CompuMethod_MCUM_FaultDataRec_State: raw=phys for phys 0..15
  compu method CompuMethod_EOL_CRC_13B: raw=phys for phys 0..255
  compu method CompuMethod_VCU_MDrvRequesSpeed: raw=phys+17000 for phys -17000..17000
  compu method CompuMethod_Debug_MCU_WarningLevel: raw=phys for phys 0..3
  compu method CompuMethod_MCUM_CRC_CA: raw=phys for phys 0..255
  compu method CompuMethod_Harness_igbt_temp1: raw=phys+50 for phys -50..205
  compu method CompuMethod_ECM_UDS_Res_Byte3: raw=phys for phys 0..1
  compu method CompuMethod_MCUM_FaultData60: raw=phys for phys 0..255
  compu method CompuMethod_BMS_Precharge_CoolingSts: raw=phys for phys 0..3
  compu method CompuMethod_EOL_GearLeverValid: raw=phys for phys 0..1
  compu method CompuMethod_VCU_Pwr_WheelMaxRecTrq: raw=phys*0.1 for phys 0..10000
  compu method CompuMethod_IBS_RollingCounter_225: raw=phys for phys 0..15
  compu method CompuMethod_MCUM_FaultData39: raw=phys for phys 0..255
  compu method CompuMethod_VCU_EolCfg_MotDrvStructure: raw=phys for phys 0..3
  compu method CompuMethod_MCUS_DragSts: raw=phys for phys 0..3
  compu method CompuMethod_EOL_ModeCMD_Data1: raw=phys for phys 0..255
  compu method CompuMethod_TMS_PTCPowerSet: raw=phys*0.02 for phys 0..10000
  compu method CompuMethod_ICU_WLTC_oilMileage: raw=phys for phys 0..2000
  compu method CompuMethod_IMParaIdent_Lm: raw=phys*1000000 for phys 0..0.01
  compu method CompuMethod_Debug_MCU_ActualTorqueFBVD: raw=phys for phys 0..1
  compu method CompuMethod_EOL_FDrvControlModeVD: raw=phys for phys 0..1
  compu method CompuMethod_BMS_Req_Cab220VInverter_Sts: raw=phys for phys 0..1
  compu method CompuMethod_VCU_EolCfg_DCChgRelayPos: raw=phys for phys 0..3
  compu method CompuMethod_ECM_EngineStartReq: raw=phys for phys 0..7
  compu method CompuMethod_VCU_MCUMMaxPosDampgTrq: raw=phys for phys 0..50
  compu method CompuMethod_VCU_Lv_SleepSatisfiedSts: raw=phys for phys 0..1
  compu method CompuMethod_VCU_BCM_Authentication_MAC_A15: raw=phys for phys 0..255
  compu method CompuMethod_MCUS_MILlampReq: raw=phys for phys 0..1
  compu method CompuMethod_VCU_Chg_AcInverterConSts: raw=phys for phys 0..1
  compu method CompuMethod_MCUM_UDS_ProductModel2: raw=phys for phys 0..255
  compu method CompuMethod_VCU_TurtleLamp: raw=phys for phys 0..1
  compu method CompuMethod_GainIden_OverRange: raw=phys for phys 0..1
  compu method CompuMethod_VCU_Ped_AccPedHPwrVolt: raw=phys*10 for phys 0..12
  compu method CompuMethod_VCU_LPedalModeSts: raw=phys for phys 0..3
  compu method CompuMethod_IVI_Minute: raw=phys for phys 0..59
  compu method CompuMethod_Debug_MCU_SelfCheckSts: raw=phys for phys 0..3
  compu method CompuMethod_IVI_DeliveryModeReq: raw=phys for phys 0..3
  compu method CompuMethod_VCU_FuelTankFlapSts: raw=phys for phys 0..1
  compu method CompuMethod_MCUM_L2agRtrElecDiff: raw=phys for phys 0..15
  compu method CompuMethod_Harness_I_V: raw=phys*20.48001049 for phys 0..12.4512
  compu method CompuMethod_IVI_InventerLimitOdometerkm: raw=phys for phys 0..4000
  compu method CompuMethod_MCUM_DrvPCBCurr: raw=phys*10 for phys 0..3
  compu method CompuMethod_VCU_BCM_Authentication_Challenge_B2: raw=phys for phys 0..255
  compu method CompuMethod_VCU_PDUHVIL_Sts: raw=phys for phys 0..1
  compu method CompuMethod_MCUM_FaultData7: raw=phys for phys 0..255
  compu method CompuMethod_MCUM_WarningLevel: raw=phys for phys 0..3
  compu method CompuMethod_R16_CMD1: raw=phys*10000+32768 for phys -3.2768..3.2767
  compu method CompuMethod_VCU_VehicleDirectS_VD: raw=phys for phys 0..1
  compu method CompuMethod_EOL_FDrvRequestTorque: raw=phys*10+5000 for phys -500..500
  compu method CompuMethod_MCUS_HighVoltPowerOffReq: raw=phys for phys 0..1
  compu method CompuMethod_S16_CMD2: raw=phys+32768 for phys -32768..32767
  compu method CompuMethod_MCUM_HeatPwrAct: raw=phys*0.01 for phys 0..12800
  compu method CompuMethod_EOL_RDrvControlMode: raw=phys for phys 0..1
  compu method CompuMethod_CDU_ACChg_HIVSts: raw=phys for phys 0..1
  compu method CompuMethod_PosDly_IdentFail_Flag: raw=phys for phys 0..1
  compu method CompuMethod_BCM_VCU_Authentication_Challenge_A3: raw=phys for phys 0..255
  compu method CompuMethod_BCM_VCU_Authentication_MAC_B13: raw=phys for phys 0..255
  compu method CompuMethod_MCUM_HeatFdBck: raw=phys for phys 0..3
  compu method CompuMethod_VCU_MCUSClutchPosition: raw=phys for phys 0..3
  compu method CompuMethod_ECM_SVSLampRequest: raw=phys for phys 0..1
  compu method CompuMethod_MCUM_Damp_CompTorque: raw=phys+500 for phys -500..500
  compu method CompuMethod_MCUM_UDS_ProductModel3: raw=phys for phys 0..255
  compu method CompuMethod_VCU_Alw_Cab220VInverter_Sts: raw=phys for phys 0..1
  compu method CompuMethod_MCUM_WaterPumpLevlReq: raw=phys*0.1 for phys 0..100
  compu method CompuMethod_VCU_Pwr_WheelPwrOvrLimitflgRE: raw=phys for phys 0..3
  compu method CompuMethod_VCU_FaultData{15..31}: raw=phys for phys 0..255
  compu method CompuMethod_VCU_VehSpdLimtRemind_ID514: raw=phys for phys 0..1
  compu method CompuMethod_MCUM_FaultData38: raw=phys for phys 0..255
  compu method CompuMethod_GW_BZCU_ACChgExitTemp_Pos: raw=phys+40 for phys -40..210
  compu method CompuMethod_VCU_VehicleDirect: raw=phys for phys 0..1
  compu method CompuMethod_MCUS_DrvMotorRPM: raw=phys+17000 for phys -17000..30000
  compu method CompuMethod_Harness_crash_err_flag: raw=phys for phys 0..1
  compu method CompuMethod_GTC_ThetaNeg: raw=phys*100 for phys 0..360
  compu method CompuMethod_IMParaIdent_ParEstMainStep: raw=phys for phys 0..10
  compu method CompuMethod_R16_CMD2: raw=phys*10000+32768 for phys -3.2768..3.2767
  compu method CompuMethod_MCUM_EOP_DCCurr: raw=phys*10 for phys 0..50
  compu method CompuMethod_VCU_PGearFlashSts: raw=phys for phys 0..1
  compu method CompuMethod_Harness_MotorTemp2: raw=phys+50 for phys -50..65485
  compu method CompuMethod_MCUM_HWOC_RstCnt: raw=phys for phys 0..15
  compu method CompuMethod_MCUM_FaultData63: raw=phys for phys 0..255
  compu method CompuMethod_PosDly_FauPro_SpdDn_OTm_Flag: raw=phys for phys 0..1
  compu method CompuMethod_VCU_SVSLamp: raw=phys for phys 0..1
  compu method CompuMethod_ECM_UDS_Res_Byte7: raw=phys for phys 0..1
  compu method CompuMethod_GW_IBC_FLWheelSpeedVD: raw=phys for phys 0..1
  compu method CompuMethod_BCM_RLDoorSts: raw=phys for phys 0..1
  compu method CompuMethod_ECM_EngineSpeed: raw=phys for phys 0..8191
  compu method CompuMethod_BCM_VCU_Authentication_MAC_B5: raw=phys for phys 0..255
  compu method CompuMethod_GCU_Operating_Mode: raw=phys for phys 0..14
  compu method CompuMethod_MCUM_FaultData20: raw=phys for phys 0..255
  compu method CompuMethod_OBC_ACChargeOutputSts: raw=phys for phys 0..1
  compu method CompuMethod_OBC_DCCurr: raw=phys*10+1000 for phys -100..100
  compu method CompuMethod_MCUM_PowerReduceSts: raw=phys for phys 0..1
  compu method CompuMethod_BCM_VCU_Authentication_MAC_B4: raw=phys for phys 0..255
  compu method CompuMethod_EddyCur_Stage: raw=phys for phys 0..5
  compu method CompuMethod_BMS_ChargerACInput: raw=phys for phys 0..1
  compu method CompuMethod_VCU_HighVoltFailed_S: raw=phys for phys 0..1
  compu method CompuMethod_DCDC_RollingCounter_324: raw=phys for phys 0..15
  compu method CompuMethod_DelayIden_Rslt_W: raw=phys for phys 0..5000
  compu method CompuMethod_VCU_FuelConsumption: raw=phys*0.25 for phys 0..1020
  compu method CompuMethod_BMS_BattIOutletTemp: raw=phys+40 for phys -40..210
  compu method CompuMethod_VCU_VehiMode_ChgMode: raw=phys for phys 0..3
  compu method CompuMethod_GW_IBC_RRWheelSpeedKPH: raw=phys*100 for phys 0..450
  compu method CompuMethod_ICU_FuelPercent: raw=phys*10 for phys 0..100
  compu method CompuMethod_VCU_GCUControlMode: raw=phys for phys 0..1
  compu method CompuMethod_Debug_MCU_RollingCounter_CA: raw=phys for phys 0..15
  compu method CompuMethod_Debug_MCU_ActiveReleaseSts: raw=phys for phys 0..3
  compu method CompuMethod_VCU_EngineIdleSpeed: raw=phys for phys 0..2
  compu method CompuMethod_MCUM_LUT_Spd_Max: raw=phys for phys 0..17000
  compu method CompuMethod_VCU_CCMHVILSts: raw=phys for phys 0..1
  compu method CompuMethod_VCU_GCURequestTorque: raw=phys*10+2000 for phys -200..200
  compu method CompuMethod_MotClb_OfsSet: raw=phys*100 for phys 0..360
  compu method CompuMethod_VCU_Hv_SelfChkSts: raw=phys for phys 0..1
  compu method CompuMethod_TMS_MainMotPumpErrSts: raw=phys for phys 0..15
  compu method CompuMethod_BCM_ACChrgPwr_Volt_ID291: raw=phys*5 for phys 0..51
  compu method CompuMethod_VCU_BCM_Authentication_MAC_A8: raw=phys for phys 0..255
  compu method CompuMethod_IBS_Warning_Level: raw=phys for phys 0..3
  compu method CompuMethod_MCUM_SelfCheckSts: raw=phys for phys 0..3
  compu method CompuMethod_VCU_WarmUpCycleIndicator: raw=phys for phys 0..1
  compu method CompuMethod_VCU_MDrvRequestTorqueVD: raw=phys for phys 0..1
  compu method CompuMethod_GCU_SelfCheck: raw=phys for phys 0..3
  compu method CompuMethod_MCUM_EOP_Temp: raw=phys+50 for phys -50..200
  compu method CompuMethod_BCM_RollingCounter_291: raw=phys for phys 0..15
  compu method CompuMethod_BCM_KeyPosition_ON2A: raw=phys for phys 0..1
  compu method CompuMethod_VCU_SDrvRequestTorque: raw=phys*10+5000 for phys -500..500
  compu method CompuMethod_GCU_ActualMotorTorque: raw=phys*10+2000 for phys -200..200
  compu method CompuMethod_BMS_ThermalManageRequest: raw=phys for phys 0..7
  compu method CompuMethod_BMS_PTCHVILSts: raw=phys for phys 0..1
  compu method CompuMethod_BMS_HVOffSts: raw=phys for phys 0..1
  compu method CompuMethod_ECM_AirPressure: raw=phys*128.2051282 for phys 0..1.9812
  compu method CompuMethod_S16_CMD3: raw=phys+32768 for phys -32768..32767
  compu method CompuMethod_BMS_ChgStopReason: raw=phys for phys 0..63
  compu method CompuMethod_R16_CMD3: raw=phys*10000+32768 for phys -3.2768..3.2767
  compu method CompuMethod_MCUM_FaultData29: raw=phys for phys 0..255
  compu method CompuMethod_MCUM_HWFault_RstCnt: raw=phys for phys 0..15
  compu method CompuMethod_BMS_CorrectSOEPer: raw=phys*10 for phys 0..100
  compu method CompuMethod_BCM_VCU_Authentication_Challenge_A2: raw=phys for phys 0..255
  compu method CompuMethod_MCUM_MotBlockHeat_CurAngle: raw=phys for phys 0..360
  compu method CompuMethod_VCU_FTorqueReqValid: raw=phys for phys 0..1
  compu method CompuMethod_VCU_AccPedalFaultLV: raw=phys for phys 0..7
  compu method CompuMethod_DelayIden_Iden_Finish: raw=phys for phys 0..1
  compu method CompuMethod_MCUS_ActualTorqueFB: raw=phys*10+5000 for phys -500..500
  compu method CompuMethod_BCM_VCU_Authentication_MAC_B6: raw=phys for phys 0..255
  compu method CompuMethod_MCUM_UDS_ProductModel15: raw=phys for phys 0..255
  compu method CompuMethod_MCUM_UDS_ProductModel1: raw=phys for phys 0..255
  compu method CompuMethod_VCU_DIn_DcChgPwr: raw=phys for phys 0..1
  compu method CompuMethod_VCU_VehicleHighVoltMode: raw=phys for phys 0..7
  compu method CompuMethod_VCU_FaultData14: raw=phys for phys 0..255
  compu method CompuMethod_MCUM_ASC_Soft_Exiting_Flag: raw=phys for phys 0..1
  compu method CompuMethod_VCU_ChrgDischrgFunSts: raw=phys for phys 0..15
  compu method CompuMethod_BMS_RHighVolSts: raw=phys for phys 0..1
  compu method CompuMethod_ECM_UDS_Res_Byte2: raw=phys for phys 0..1
  compu method CompuMethod_MCUM_UDS_HW9: raw=phys for phys 0..255
  compu method CompuMethod_IVI_FuelupReq: raw=phys for phys 0..1
  compu method CompuMethod_IVI_FuelChgLevel: raw=phys for phys 0..3
  compu method CompuMethod_IVI_FuelChgMode: raw=phys for phys 0..1
  compu method CompuMethod_MCUM_FaultData2: raw=phys for phys 0..255
  compu method CompuMethod_GainIden_CurrRMS_Ref_W: raw=phys*10 for phys 0..800
  compu method CompuMethod_MCUM_UDS_Supplier4: raw=phys for phys 0..255
  compu method CompuMethod_VCU_VehicleDirectVD: raw=phys for phys 0..1
  compu method CompuMethod_MCUM_UDS_ProductModel7: raw=phys for phys 0..255
  compu method CompuMethod_MCUM_UDS_ProductModel12: raw=phys for phys 0..255
  compu method CompuMethod_VCU_BCM_Authentication_MAC_A3: raw=phys for phys 0..255
  compu method CompuMethod_MCUM_SBC_SPIFault: raw=phys for phys 0..1
  compu method CompuMethod_VCU_CDU_RecvTr: raw=phys for phys 0..1
  compu method CompuMethod_MCUM_UDS_ProductModel11: raw=phys for phys 0..255
  compu method CompuMethod_OfsIden_DirWrite_Finish: raw=phys for phys 0..1
  compu method CompuMethod_GW_BZCU_DCChgExitTemp_Neg: raw=phys+40 for phys -40..210
  compu method CompuMethod_EddyCur_Para_Cos_Pha: raw=phys*10000+20000 for phys -2..2
  compu method CompuMethod_ECM_IdleActive: raw=phys for phys 0..1
  compu method CompuMethod_ECM_EngineTorqueMin: raw=phys*2+1000 for phys -500..1547
  compu method CompuMethod_ICU_CLTC_ElectticityMileage: raw=phys for phys 0..2000
  compu method CompuMethod_EOL_ModeCMD_Data4: raw=phys for phys 0..255
  compu method CompuMethod_GW_BZCU_ACChgLockSts: raw=phys for phys 0..3
  compu method CompuMethod_MCUM_UDS_ProductModel5: raw=phys for phys 0..255
  compu method CompuMethod_ECM_FanSts: raw=phys for phys 0..100
  compu method CompuMethod_MCUM_UDS_HW10: raw=phys for phys 0..255
  compu method CompuMethod_BMS_BMU_SoftwareVersion: raw=phys for phys 0..16000000
  compu method CompuMethod_EddyCur_Para_Cos_m: raw=phys+2048 for phys -2000..2000
  compu method CompuMethod_TMS_MCUOutTemp: raw=phys+50 for phys -50..200
  compu method CompuMethod_TMS_MCUSIntelTemp: raw=phys+50 for phys -50..200
  compu method CompuMethod_MCUM_Torque_ExtChar: raw=phys for phys 0..500
  compu method CompuMethod_VCU_FuelDectionModeSts: raw=phys for phys 0..3
  compu method CompuMethod_BCM_VCU_Authentication_MAC_B1: raw=phys for phys 0..255
  compu method CompuMethod_BMS_RPreChargeFinishSts: raw=phys for phys 0..3
  compu method CompuMethod_MCUM_UserDefine_Byte3: raw=phys for phys 0..255
  compu method CompuMethod_VCU_REHighPerformVehiPwr: raw=phys*2 for phys 0..127
  compu method CompuMethod_VCU_REPwrDampingFactor: raw=phys*2 for phys 0..127
  compu method CompuMethod_VCU_REDrvTarPwrFit: raw=phys*2 for phys 0..511
  compu method CompuMethod_MCUM_Spd_Delta: raw=phys+2000 for phys -2000..2000
  compu method CompuMethod_IMParaIdent_Ll: raw=phys*1000000 for phys 0..0.01
  compu method CompuMethod_MCUM_12VHop_Cnt: raw=phys for phys 0..15
  compu method CompuMethod_GW_IBC_RLWheelSpeedKPH: raw=phys*100 for phys 0..450
  compu method CompuMethod_MotClb_Id_Fb: raw=phys*10+10000 for phys -1000..1000
  compu method CompuMethod_MCUM_FaultData3: raw=phys for phys 0..255
  compu method CompuMethod_EOL_ModeCMD_Enable: raw=phys for phys 0..255
  compu method CompuMethod_GCU_MoterTemp: raw=phys+40 for phys -40..210
  compu method CompuMethod_MCUM_PWM_Freq_kHz: raw=phys*10 for phys 0..25.5
  compu method CompuMethod_BMS_RPositiveRelayFB: raw=phys for phys 0..1
  compu method CompuMethod_MCUM_ASC_EntryCount: raw=phys for phys 0..31
  compu method CompuMethod_VCU_FaultData2: raw=phys for phys 0..255
  compu method CompuMethod_MCUM_PWM_State: raw=phys for phys 0..3
  compu method CompuMethod_VCU_HeatPwrAval: raw=phys for phys 0..31
  compu method CompuMethod_VCU_EolCfg_InverterFunc: raw=phys for phys 0..1
  compu method CompuMethod_MCUM_FaultData19: raw=phys for phys 0..255
  compu method CompuMethod_EOL_GainIden_UsApply: raw=phys*1000 for phys 0..0.4
  compu method CompuMethod_ECM_RestrictorOpenValue: raw=phys for phys 0..100
  compu method CompuMethod_MCUM_Power_15V: raw=phys*10 for phys 0..25
  compu method CompuMethod_MCUM_UDS_ProductModel14: raw=phys for phys 0..255
  compu method CompuMethod_OBC_WorkSts: raw=phys for phys 0..7
  compu method CompuMethod_OBC_CCConnectSts: raw=phys for phys 0..3
  compu method CompuMethod_VCU_MDrvFilterTrqRange: raw=phys for phys 0..7
  compu method CompuMethod_ECM_SWVersionC: raw=phys for phys 0..254
  compu method CompuMethod_MotClb_ThtSetReal: raw=phys*10+10000 for phys -1000..1000
  compu method CompuMethod_BMS_WkupVolt_DC12V: raw=phys*5 for phys 0..50
  compu method CompuMethod_VCU_EolCfg_VehiType: raw=phys for phys 0..1
  compu method CompuMethod_ECM_EngineWorktime: raw=phys for phys 0..65535
  compu method CompuMethod_VCU_InverterTip: raw=phys for phys 0..7
  compu method CompuMethod_VCU_MCUMMaxDischargePower: raw=phys for phys 0..510
  compu method CompuMethod_IVI_Second: raw=phys for phys 0..59
  compu method CompuMethod_VCU_BCM_Authentication_MAC_A5: raw=phys for phys 0..255
  compu method CompuMethod_MCUM_FaultData24: raw=phys for phys 0..255
  compu method CompuMethod_MCUM_DCChargRelaySts: raw=phys for phys 0..1
  compu method CompuMethod_BSW_VertifySts: raw=phys for phys 0..3
  compu method CompuMethod_Debug_MCU_MainWireCurr: raw=phys*10+10000 for phys -1000..1000
  compu method CompuMethod_ECM_EngineCoolantTemp: raw=phys+40 for phys -40..215
  compu method CompuMethod_MCUM_FaultData9: raw=phys for phys 0..1.8446744073709552e+19
  compu method CompuMethod_BCM_VCU_Authentication_MAC_B0: raw=phys for phys 0..255
  compu method CompuMethod_S16_CMD1: raw=phys+32768 for phys -32768..32767
  compu method CompuMethod_ECM_FuelLevelSensorValid: raw=phys for phys 0..1
  compu method CompuMethod_BMS_MaxChargeVolt: raw=phys*10 for phys 0..1000
  compu method CompuMethod_OfsIden_MtrLock: raw=phys for phys 0..1
  compu method CompuMethod_MCUM_UDS_Boot1: raw=phys for phys 0..255
  compu method CompuMethod_VCU_BCM_Authentication_Sts: raw=phys for phys 0..3
  compu method CompuMethod_MCUM_UDS_Boot7: raw=phys for phys 0..255
  compu method CompuMethod_VCU_AlwACChargeInventerSts: raw=phys for phys 0..1
  compu method CompuMethod_BCM_PTCRollCntErr: raw=phys for phys 0..1
  compu method CompuMethod_VCU_BCM_Authentication_MAC_A9: raw=phys for phys 0..255
  compu method CompuMethod_BMS_RPositiveRelay_F: raw=phys for phys 0..1
  compu method CompuMethod_MCUM_LUT_Spd: raw=phys for phys 0..17000
  compu method CompuMethod_U16_CMD2: raw=phys for phys 0..65535
  compu method CompuMethod_MCUM_NVM_IGBTTypeRFault: raw=phys for phys 0..1
  compu method CompuMethod_BCM_VCU_Authentication_Challenge_A0: raw=phys for phys 0..255
  compu method CompuMethod_ICU_CRC_DF: raw=phys for phys 0..255
  compu method CompuMethod_ICU_RollingCounter_DF: raw=phys for phys 0..15
  compu method CompuMethod_ICU_IMU_ACC_x: raw=phys*512+32768 for phys -64..63.998
  compu method CompuMethod_ICU_IMU_ACC_y: raw=phys*512+32768 for phys -64..63.998
  compu method CompuMethod_ICU_IMU_ACC_z: raw=phys*512+32768 for phys -64..63.998
  compu method CompuMethod_ICU_IMU_ACC_Roll_Rate: raw=phys*100+32768 for phys -327.68..327.67
  compu method CompuMethod_ICU_IMU_ACC_Pitch_Rate: raw=phys*100+32768 for phys -327.68..327.67
  compu method CompuMethod_ICU_IMU_ACC_Yaw_Rate: raw=phys*100+32768 for phys -327.68..327.67
  compu method CompuMethod_ICU_IMU_Calibrated: raw=phys for phys 0..2
  compu method CompuMethod_ICU_IMU_Valid: raw=phys for phys 0..1
  compu method CompuMethod_MCUM_PWMEn_State: raw=phys for phys 0..1
  compu method CompuMethod_BMS_MaxChargeCurr: raw=phys*10 for phys 0..400
  compu method CompuMethod_VCU_DeliveryModeSts: raw=phys for phys 0..1
  compu method CompuMethod_VCU_ChargePauseReq: raw=phys for phys 0..1
  compu method CompuMethod_BCM_ON2InitiativeSts: raw=phys for phys 0..1
  compu method CompuMethod_EOL_FDrvControlMode: raw=phys for phys 0..1
  compu method CompuMethod_VCU_EolCfg_VehiModels: raw=phys for phys 0..7
  compu method CompuMethod_MCUM_LVSystemError: raw=phys for phys 0..1
  compu method CompuMethod_GW_IBC_RAB_Avatiable: raw=phys for phys 0..1
  compu method CompuMethod_OBC_ACVolt: raw=phys*10 for phys 0..800
  compu method CompuMethod_MotClb_Power_Inverter: raw=phys*10+10000 for phys -1000..1000
  compu method CompuMethod_VCU_MilReq_DTC: raw=phys for phys 0..254
  compu method CompuMethod_ECM_GPFRegenReq: raw=phys for phys 0..1
  compu method CompuMethod_VCU_EmergencyStopReq: raw=phys for phys 0..1
  compu method CompuMethod_MCUM_FaultData6: raw=phys for phys 0..255
  compu method CompuMethod_OBC_ACPowerState: raw=phys for phys 0..3
  compu method CompuMethod_EddyCur_FauPro_IDPara_OVal_Flag: raw=phys for phys 0..1
  compu method CompuMethod_BCM_VCU_Authentication_MAC_B8: raw=phys for phys 0..255
  compu method CompuMethod_GW_BZCU_FuelTankLockCtrl: raw=phys for phys 0..3
  compu method CompuMethod_VCU_MDrvControlModeVD: raw=phys for phys 0..1
  compu method CompuMethod_BMS_ChargeQuantity: raw=phys*2 for phys 0..500
  compu method CompuMethod_TMS_OutsideTempVD: raw=phys for phys 0..1
  compu method CompuMethod_MCUM_UDS_ProductModel6: raw=phys for phys 0..255
  compu method CompuMethod_VCU_ON2BRelayReq: raw=phys for phys 0..3
  compu method CompuMethod_U8_CMD7: raw=phys for phys 0..255
  compu method CompuMethod_MCUM_NMControl_PNI: raw=phys for phys 0..1
  compu method CompuMethod_GW_TCM_CRC_30B: raw=phys for phys 0..255
  compu method CompuMethod_BCM_VCU_Authentication_MAC_B14: raw=phys for phys 0..255
  compu method CompuMethod_VCU_FaultData13: raw=phys for phys 0..255
  compu method CompuMethod_BCM_PTCLossMissErr: raw=phys for phys 0..1
  compu method CompuMethod_EOL_RDrvRequesSpeed: raw=phys+17000 for phys -17000..17000
  compu method CompuMethod_VCU_Hv_HvOffSts: raw=phys for phys 0..15
  compu method CompuMethod_MCUM_StatorTemp_1: raw=phys+50 for phys -50..200
  compu method CompuMethod_MCUM_L2TqAct: raw=phys+50 for phys -50..1023
  compu method CompuMethod_MCUM_EOPSw: raw=phys+50 for phys -50..131071
  compu method CompuMethod_MCUS_Clutch_Pos: raw=phys for phys 0..7
  compu method CompuMethod_EOL_BrakePedalValue: raw=phys*2.544529262 for phys 0..100
  compu method CompuMethod_BMS_Req_Cabin220VInverter_Sts: raw=phys for phys 0..1
  compu method CompuMethod_BCM_ACChgLockCtrl: raw=phys for phys 0..3
  compu method CompuMethod_VCU_BCM_Authentication_MAC_A11: raw=phys for phys 0..255
  compu method CompuMethod_VCU_PowerReducetSts: raw=phys for phys 0..1
  compu method CompuMethod_MCUM_HVSystemError: raw=phys for phys 0..1
  compu method CompuMethod_MCUM_FaultData53: raw=phys for phys 0..255
  compu method CompuMethod_VCU_BCM_Authentication_MAC_A12: raw=phys for phys 0..255
  compu method CompuMethod_BCM_VCU_Authentication_MAC_B10: raw=phys for phys 0..255
  compu method CompuMethod_VCU_CcmHvilInSigFreq_FB: raw=phys for phys 0..200
  compu method CompuMethod_MCUM_EOP_IqFb: raw=phys*10 for phys 0..50
  compu method CompuMethod_GCU_RollingCounter_BD: raw=phys for phys 0..15
  compu method CompuMethod_VCU_VacuumDegree: raw=phys*2.544529262 for phys 0..100
  compu method CompuMethod_MCUM_MinTorqueAllow: raw=phys*10+5000 for phys -500..500
  compu method CompuMethod_MCUM_Vbus_ServeLowChkEn: raw=phys for phys 0..1
  compu method CompuMethod_IVI_ForceChgTargetSOC: raw=phys for phys 0..100
  compu method CompuMethod_BMS_ACPTCHVILSts: raw=phys for phys 0..1
  compu method CompuMethod_MCUM_UserDefine_Word2: raw=phys for phys 0..65535
  compu method CompuMethod_MCUM_Id_Fb: raw=phys+1000 for phys -1000..1000
  compu method CompuMethod_MCUM_JuncTemp_Max: raw=phys*10 for phys 0..400
  compu method CompuMethod_BCM_BackDoorSts: raw=phys for phys 0..1
  compu method CompuMethod_ECM_learningReq: raw=phys for phys 0..1
  compu method CompuMethod_VCU_Pwr_LossFlg: raw=phys for phys 0..1
  compu method CompuMethod_MCUM_EOL_CANCommReq: raw=phys for phys 0..1
  compu method CompuMethod_GainIden_CurrRMS_Ref_V: raw=phys*10 for phys 0..800
  compu method CompuMethod_EOL_MotClb_IsCMD: raw=phys+17000 for phys -17000..48535
  compu method CompuMethod_Harness_MotorTemp1: raw=phys+50 for phys -50..65485
  compu method CompuMethod_OfsIden_OfsRslt: raw=phys*10 for phys 0..360
  compu method CompuMethod_MCUS_MaxTorqueAllow: raw=phys*10+5000 for phys -500..500
  compu method CompuMethod_BCM_VCU_Authentication_MAC_B3: raw=phys for phys 0..255
  compu method CompuMethod_MCUM_UDS_HW5: raw=phys for phys 0..255
  compu method CompuMethod_MCUM_EOP_Speed: raw=phys*0.6825938567+4095.56314 for phys -6000..5999.82
  compu method CompuMethod_VCU_VehichRealPwDown: raw=phys for phys 0..255
  compu method CompuMethod_MotClb_FaultCode5: raw=phys for phys 0..255
  compu method CompuMethod_BMS_RollingCounter_1A1: raw=phys for phys 0..15
  compu method CompuMethod_EOL_RDrvControlModeVD: raw=phys for phys 0..1
  compu method CompuMethod_VCU_CalibrationNumber: raw=phys for phys 0..7
  compu method CompuMethod_BMS_BattMaxTemp: raw=phys+40 for phys -40..210
  compu method CompuMethod_VCU_ThrottlePosition: raw=phys*2.544529262 for phys 0..100
  compu method CompuMethod_GW_BZCU_Cab_220VRelay_CtrlSts: raw=phys for phys 0..1
  compu method CompuMethod_PosDly_FauPro_Ident_OTm_Flag: raw=phys for phys 0..1
  compu method CompuMethod_VCU_FaultData11: raw=phys for phys 0..255
  compu method CompuMethod_Debug_MCU_MaxSpeedAllow: raw=phys+17000 for phys -17000..17000
  compu method CompuMethod_VCU_BMSMainRelayR_Cmd: raw=phys for phys 0..1
  compu method CompuMethod_MCUM_FaultData35: raw=phys for phys 0..255
  compu method CompuMethod_OfsIden_SpdUp_OverSpd: raw=phys for phys 0..1
  compu method CompuMethod_VCU_EngineRunAllowFlg: raw=phys for phys 0..1
  compu method CompuMethod_MCUM_DragSts: raw=phys for phys 0..3
  compu method CompuMethod_DelayIden_Rslt_Avg: raw=phys for phys 0..5000
  compu method CompuMethod_VCU_PowerOverSts: raw=phys for phys 0..1
  compu method CompuMethod_VCU_EMSRepairModeSts: raw=phys for phys 0..3
  compu method CompuMethod_TMS_PTCHeatingReq: raw=phys for phys 0..1
  compu method CompuMethod_MCUM_UDS_Boot6: raw=phys for phys 0..255
  compu method CompuMethod_MCUM_UDS_HW4: raw=phys for phys 0..255
  compu method CompuMethod_GW_BZCU_LBMS_VoltA: raw=phys*10 for phys 0..18
  compu method CompuMethod_BMS_MCUSHVILSts: raw=phys for phys 0..1
  compu method CompuMethod_VCU_FaultData1: raw=phys for phys 0..255
  compu method CompuMethod_BCM_FuelTankLockReq: raw=phys for phys 0..3
  compu method CompuMethod_VCU_REsystemSts_ID514: raw=phys for phys 0..1
  compu method CompuMethod_MCUS_MinTorqueAllow: raw=phys*10+5000 for phys -500..500
  compu method CompuMethod_GW_IBC_RRWheelSpeedVD: raw=phys for phys 0..1
  compu method CompuMethod_TMS_MainMotPump_Operation_Current: raw=phys*5 for phys 0..50
  compu method CompuMethod_DelayIden_Rslt_U: raw=phys for phys 0..5000
  compu method CompuMethod_VCU_Permanent_DTC: raw=phys for phys 0..254
  compu method CompuMethod_ECM_FVVSts: raw=phys for phys 0..3
  compu method CompuMethod_MCUM_HWRdcFault: raw=phys for phys 0..1
  compu method CompuMethod_TMS_MCUMIntelTemp: raw=phys+50 for phys -50..200
  compu method CompuMethod_ECM_EngineStopInhibit: raw=phys for phys 0..1023
  compu method CompuMethod_VCU_FTorqueReq: raw=phys*2+1000 for phys -500..1547
  compu method CompuMethod_MCUS_CRC_DB: raw=phys for phys 0..255
  compu method CompuMethod_MCUS_Clutch_2_Fault: raw=phys for phys 0..1023
  compu method CompuMethod_MCUS_Clutch_1_Fault: raw=phys for phys 0..1023
  compu method CompuMethod_MCUS_Clutch_2_WarningLevel: raw=phys for phys 0..3
  compu method CompuMethod_MCUS_Clutch_1_WarningLevel: raw=phys for phys 0..3
  compu method CompuMethod_MCUS_Clutch_2_Pos: raw=phys for phys 0..7
  compu method CompuMethod_MCUS_Clutch_1_Pos: raw=phys for phys 0..7
  compu method CompuMethod_MCUM_FaultData34: raw=phys for phys 0..255
  compu method CompuMethod_EddyCur_Enable: raw=phys for phys 0..1
  compu method CompuMethod_VCU_CcmHvilInSigDuty_FB: raw=phys for phys 0..100
  compu method CompuMethod_MCUM_UDS_SW3: raw=phys for phys 0..255
  compu method CompuMethod_DelayIden_OverRange: raw=phys for phys 0..1
  compu method CompuMethod_MCUM_FaultData55: raw=phys for phys 0..255
  compu method CompuMethod_GW_IBC_RAB_Active: raw=phys for phys 0..1
  compu method CompuMethod_EddyCur_Para_Cos_k: raw=phys*10000 for phys 0..3
  compu method CompuMethod_BMS_VoltLoDeratLevel_NA: raw=phys for phys 0..3
  compu method CompuMethod_VCU_FaultData6: raw=phys for phys 0..255
  compu method CompuMethod_VCU_LowPwr_LowBatt1Volt: raw=phys*4 for phys 0..31.75
  compu method CompuMethod_OfsIden_DirIden_Rslt: raw=phys+1 for phys -1..1
  compu method CompuMethod_VCU_GCURequesSpeed_MGCU: raw=phys+17000 for phys -17000..30000
  compu method CompuMethod_ECM_UDS_PhyReq_Byte3: raw=phys for phys 0..1
  compu method CompuMethod_TMS_MainMotPump_Supplied_Voltage: raw=phys*10 for phys 0..25.4
  compu method CompuMethod_MCUM_UDS_SW4: raw=phys for phys 0..255
  compu method CompuMethod_VCU_MMotSelfHeatLvlReq: raw=phys for phys 0..7
  compu method CompuMethod_VCU_FaultData0: raw=phys for phys 0..255
  compu method CompuMethod_EOL_MCUMMaxPosDampgTrq: raw=phys for phys 0..50
  compu method CompuMethod_VCU_BrakePedalValue: raw=phys*2.544529262 for phys 0..100
  compu method CompuMethod_GCU_ActiveReleaseFB: raw=phys for phys 0..3
  compu method CompuMethod_MCUM_UDS_SW2: raw=phys for phys 0..255
  compu method CompuMethod_OfsIden_ReadSuccess_Flag: raw=phys for phys 0..1
  compu method CompuMethod_IVI_AWDModeSW: raw=phys for phys 0..1
  compu method CompuMethod_VCU_EngLongTimeStartReq: raw=phys for phys 0..1
